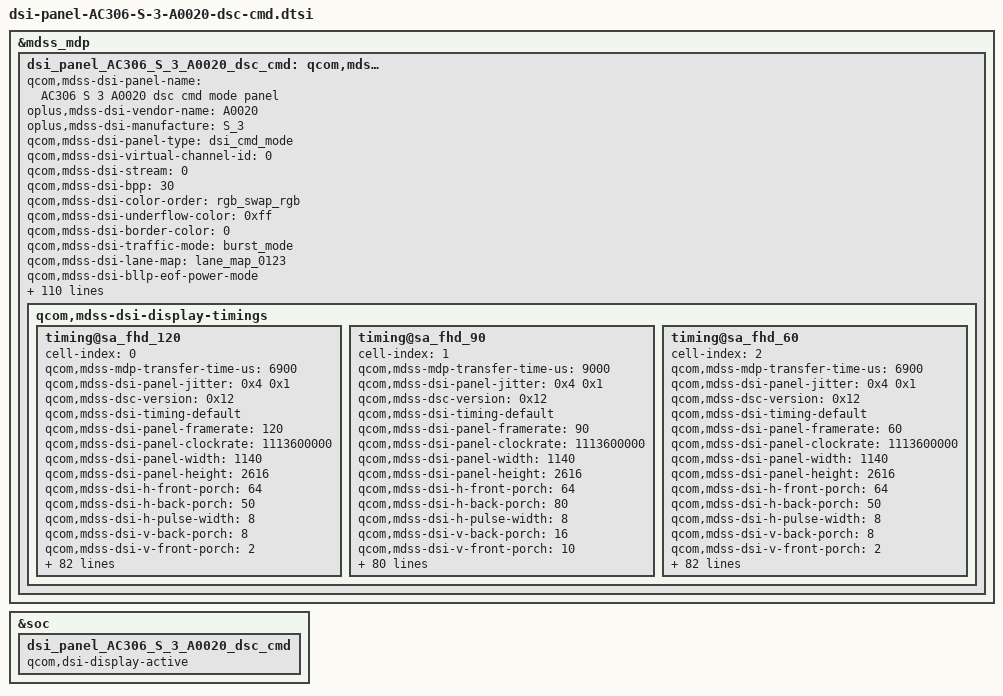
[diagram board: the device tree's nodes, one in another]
&mdss_mdp {
	dsi_panel_AC306_S_3_A0020_dsc_cmd: qcom,mdss_dsi_panel_AC306_S_3_A0020_dsc_cmd {
		qcom,mdss-dsi-panel-name = "AC306 S 3 A0020 dsc cmd mode panel";
		oplus,mdss-dsi-vendor-name = "A0020";
		oplus,mdss-dsi-manufacture = "S_3";
		qcom,mdss-dsi-panel-type = "dsi_cmd_mode";
		qcom,mdss-dsi-virtual-channel-id = <0>;
		qcom,mdss-dsi-stream = <0>;
		qcom,mdss-dsi-bpp = <30>;
		qcom,mdss-dsi-color-order = "rgb_swap_rgb";
		qcom,mdss-dsi-underflow-color = <0xff>;
		qcom,mdss-dsi-border-color = <0>;
		qcom,mdss-dsi-traffic-mode = "burst_mode";
		qcom,mdss-dsi-lane-map = "lane_map_0123";
		qcom,mdss-dsi-bllp-eof-power-mode;
		qcom,mdss-dsi-bllp-power-mode;
		qcom,mdss-dsi-lane-0-state;
		qcom,mdss-dsi-lane-1-state;
		qcom,mdss-dsi-lane-2-state;
		qcom,mdss-dsi-lane-3-state;
		qcom,mdss-dsi-dma-trigger = "trigger_sw";
		qcom,mdss-loading-effect;
		qcom,mdss-dsi-mdp-trigger = "none";
		qcom,mdss-dsi-reset-sequence = <1 2>, <0 5>, <1 30>;
		qcom,mdss-dsi-te-pin-select = <1>;
		qcom,mdss-dsi-te-dcs-command = <1>;
		qcom,mdss-pan-physical-width-dimension = <65>;
		qcom,mdss-pan-physical-height-dimension = <146>;
		qcom,mdss-dsi-init-delay-us = <1000>;
		qcom,mdss-dsi-te-check-enable;
		qcom,mdss-dsi-te-using-te-pin;
		//qcom,mdss-dsi-lp11-init;
		qcom,mdss-dsi-wr-mem-start = <0x2c>;
		qcom,mdss-dsi-wr-mem-continue = <0x3c>;
		qcom,mdss-dsi-panel-jitter = <0x4 0x1>;
		qcom,mdss-dsc-scr-version = <0x1>;
		qcom,mdss-bl-high2bit;
		/* HDR Setting */
		qcom,mdss-dsi-panel-hdr-enabled;
		qcom,mdss-dsi-panel-hdr-color-primaries = <15635 16450 34000 16000 13250 34500 7500 3000>;
		//update for [MPC15]android.mediapc.cts.PerformanceClassTest#testDisplayHdr pass
		//qcom,mdss-dsi-panel-peak-brightness = <16000000>;
		qcom,mdss-dsi-panel-peak-brightness = <22000000>;
		qcom,mdss-dsi-panel-average-brightness = <2000000>;
		qcom,mdss-dsi-panel-blackness-level = <4000>;
		qcom,dynamic-mode-switch-enabled;
		qcom,dynamic-mode-switch-type = "dynamic-resolution-switch-immediate";
		qcom,mdss-dsi-display-timings {
			timing@sa_fhd_120{
				cell-index = <0>;
				#include "dsi-panel-AC306-S-3-A0020-loading-effect.dtsi"
				#include "dsi-panel-AC306-S-3-A0020-common.dtsi"
				qcom,mdss-mdp-transfer-time-us = <6900>;
				qcom,mdss-dsi-panel-jitter = <0x4 0x1>;
				qcom,mdss-dsc-version = <0x12>;
				qcom,mdss-dsi-timing-default;
				qcom,mdss-dsi-panel-framerate = <120>;
				qcom,mdss-dsi-panel-clockrate = <1113600000>;
				qcom,mdss-dsi-panel-width = <1140>;
				qcom,mdss-dsi-panel-height = <2616>;
				qcom,mdss-dsi-h-front-porch = <64>;
				qcom,mdss-dsi-h-back-porch = <50>;
				qcom,mdss-dsi-h-pulse-width = <8>;
				qcom,mdss-dsi-v-back-porch = <8>;
				qcom,mdss-dsi-v-front-porch = <2>;
				qcom,mdss-dsi-v-pulse-width = <2>;
				qcom,mdss-dsi-h-sync-pulse = <0>;

				qcom,mdss-dsi-h-left-border = <0>;
				qcom,mdss-dsi-h-right-border = <0>;
				qcom,mdss-dsi-v-top-border = <0>;
				qcom,mdss-dsi-v-bottom-border = <0>;
				qcom,dsi-mode-te-width-us = <270>;

				/* Apollo vsync config, need to measure TE signal */
				//oplus,apollo-panel-vsync-width = <13000>;
				//oplus,apollo-panel-vsync-period = <16600>;

				oplus,fod-on-vblank = <0>;
				oplus,fod-off-vblank = <0>;

				qcom,mdss-dsi-timing-switch-command = [
					//Switch to 120Hz
					39 00 00 40 00 00 04 FF 5A A5 2D //Page 2D
					39 00 00 40 00 00 03 93 04 00
					39 00 00 40 00 00 03 83 77 00 // Decreasing Step Setting
					15 00 00 40 00 00 02 97 02
					39 00 00 40 00 00 03 98 03 00
					39 00 00 40 00 00 03 99 0B 00
					39 00 00 40 00 00 03 9A 17 00
					39 00 00 40 00 00 03 9B 00 00
					39 00 00 40 00 00 05 A0 00 01 00 00
					39 00 00 40 00 00 05 A1 02 00 00 00
					39 00 00 40 00 00 04 FF 5A A5 00 //Page 0
					15 00 00 40 00 00 02 60 00 //120hz 1 pulse
					39 00 00 40 00 00 04 FF 5A A5 2D //Page 2D
					39 00 00 40 00 00 03 83 00 00 // switch to 120hz
					15 00 00 40 00 00 02 F2 00
					39 00 00 00 00 00 04 FF 5A A5 00 //Page 0
				];
				qcom,mdss-dsi-on-command = [
					39 00 00 40 00 00 04 FF 5A A5 08 // OTP Don’t reload
					15 00 00 40 00 00 02 C8 62
					39 00 00 40 00 00 04 FF 5A A5 07
					15 00 00 40 00 00 02 8A 01
					39 00 00 40 00 00 03 8B 21 E0
					39 00 00 40 00 00 64 81 00 00 00 00 00 12 00 00 AB 21 00 0A 38 04 74 00 0C 02 3A 02 3A 01 55 01 C8 00 0A 00 97 00 2F 00 0C 08 BB 2D 7A 08 00 0C 00 07 10 20 00 06 0F 0F 33 0E 1C 2A 38 46 54 62 69 70 77 79 7B 7D 7E 00 82 11 40 19 C0 22 3E 32 7C 3A BA 3A F8 3B 38 3B 38 3B 76 4B 76 4B 74 4B 74 5B B4 73 F4 01 00 00 00 00 00
					15 00 00 40 00 00 02 91 03
					/* AP SPR */
					39 00 00 40 00 00 04 FF 5A A5 14
					15 00 00 40 00 00 02 80 00
					15 00 00 40 00 00 02 82 01
					39 00 00 00 00 00 04 FF 5A A5 00
					39 00 00 40 00 00 04 FF 5A A5 06 // 1Bist ESD
					15 00 00 40 00 00 02 C6 01
					39 00 00 40 00 00 04 FF 5A A5 08
					15 00 00 40 00 00 02 D2 05
					15 00 00 40 00 00 02 D3 01
					15 00 00 40 00 00 02 E0 22
					39 00 00 40 00 00 04 FF 5A A5 06
					15 00 00 40 00 00 02 A0 00 //scramble disable
					39 00 00 40 00 00 04 FF 5A A5 21 //Page 21
					15 00 00 40 00 00 02 A4 38 //flash reload enable
					39 00 00 40 00 00 04 FF 5A A5 08
					39 00 00 40 00 00 09 ED FF FF FF FF FF FF 45 FF
					39 00 00 40 00 00 09 EE FF FD FF FD F9 FA BE 76
					39 00 00 40 00 00 04 FF 5A A5 00 //Page 0
					15 00 00 40 00 00 02 5E 01 //Skip frame Enable
					15 00 00 40 00 00 02 60 00 //Normal = 120Hz
					15 00 00 40 00 00 02 61 03 //AOD in = 30Hz
					15 00 00 40 00 00 02 35 00 //TE On
					15 00 00 00 00 00 02 53 20 //BC On, Dimming Off
					/* DIC RCN off */
					39 00 00 40 00 00 04 FF 5A A5 17
					15 00 00 40 00 00 02 A0 00
					39 00 00 40 00 00 04 FF 5A A5 13
					15 00 00 00 00 00 02 F9 3C

					39 00 00 40 00 00 04 FF 5A A5 00 //Page 0
					15 00 00 40 00 00 02 60 00 //120hz 1 pulse
					39 00 00 40 00 00 04 FF 5A A5 2D //Page 2D
					39 00 00 40 00 00 03 83 00 00
					39 00 00 40 00 00 03 93 04 00 // Decreasing Step Setting
					15 00 00 40 00 00 02 F2 00
					39 00 00 00 00 00 04 FF 5A A5 00 //Page 0
					/* AOD on/off Black Frame Setting */
					39 00 00 40 00 00 04 FF 5A A5 02
					39 00 00 40 00 00 03 88 C0 00
					39 00 00 00 02 00 04 FF 5A A5 00
					/*sleep out*/
					05 00 00 00 78 00 01 11
					/* ODC */
					39 00 00 40 00 00 04 FF 5A A5 5A
					39 00 00 40 00 00 04 83 2F 14 10
					39 00 00 40 00 00 04 86 42 38 33
					39 00 00 40 00 00 04 8A 18 14 15
					39 00 00 40 00 00 04 8F 14 17 15
					39 00 00 40 00 00 04 90 11 14 13
					39 00 00 40 00 00 04 91 12 16 12
					39 00 00 40 00 00 04 95 18 1D 1D
					39 00 00 40 00 00 04 96 18 18 18
					39 00 00 40 00 00 04 97 12 15 12
					39 00 00 40 00 00 04 98 10 16 12
					39 00 00 40 00 00 04 AA 18 10 13
					39 00 00 40 00 00 04 AC 00 05 04
					39 00 00 40 00 00 04 AD 00 05 04
					39 00 00 40 00 00 04 AE 16 12 10
					39 00 00 40 00 00 04 AF 10 10 10
					39 00 00 40 00 00 04 B0 0D 0D 0D
					39 00 00 40 00 00 04 B1 00 02 00
					39 00 00 40 00 00 04 B2 00 02 00
					39 00 00 40 00 00 04 B3 1D 16 24
					39 00 00 40 00 00 04 B4 14 16 14
					39 00 00 40 00 00 04 B7 06 04 06
					39 00 00 40 00 00 04 B8 05 04 05
					39 00 00 40 00 00 04 B9 30 28 30
					39 00 00 40 00 00 04 BE 07 04 07
					39 00 00 40 00 00 04 BF 06 04 06
					39 00 00 40 00 00 04 C0 39 36 3E
					39 00 00 40 00 00 04 CB 06 08 08
					39 00 00 40 00 00 04 CE 0A 0B 0A
					39 00 00 40 00 00 04 D0 03 05 04
					39 00 00 40 00 00 04 D2 0A 0D 0B
					39 00 00 40 00 00 04 D5 06 02 07
					39 00 00 40 00 00 04 D6 06 02 06
					39 00 00 40 00 00 04 DB 06 03 06
					39 00 00 40 00 00 04 DC 06 03 06
					39 00 00 40 00 00 04 E2 06 02 06
					39 00 00 40 00 00 04 E3 06 02 06
					39 00 00 40 00 00 04 E4 32 36 36
					39 00 00 40 00 00 04 FF 5A A5 5B
					39 00 00 40 00 00 04 A5 04 0A 04
					39 00 00 40 00 00 04 A6 04 06 06
					39 00 00 40 00 00 04 A7 06 08 08
					39 00 00 40 00 00 04 A8 06 0A 08
					39 00 00 40 00 00 04 A9 02 02 02
					39 00 00 40 00 00 04 B1 06 03 06
					39 00 00 40 00 00 04 B2 06 03 06
					39 00 00 40 00 00 04 B9 30 22 30
					39 00 00 40 00 00 04 BE 08 06 06
					39 00 00 40 00 00 04 BF 08 06 06
					39 00 00 40 00 00 04 C0 41 44 45
					39 00 00 40 00 00 04 C9 02 04 04
					39 00 00 40 00 00 04 DB 02 0C 05
					39 00 00 40 00 00 04 DC 02 09 04
					39 00 00 40 00 00 04 E2 02 10 07
					39 00 00 40 00 00 04 E3 02 0D 08
					39 00 00 40 00 00 04 E4 30 36 36
					39 00 00 40 00 00 04 EA 02 11 08
					39 00 00 40 00 00 04 EB 02 0F 05
					39 00 00 40 00 00 04 FF 5A A5 5C
					39 00 00 40 00 00 04 88 04 06 06
					39 00 00 40 00 00 04 89 02 06 05
					39 00 00 40 00 00 04 8A 1A 16 19
					39 00 00 40 00 00 04 8B 1A 16 17
					39 00 00 40 00 00 04 8C 16 12 13
					39 00 00 40 00 00 04 8D 0A 03 08
					39 00 00 40 00 00 04 8E 06 02 03
					39 00 00 40 00 00 04 93 02 06 05
					39 00 00 40 00 00 04 94 02 06 04
					39 00 00 40 00 00 04 95 30 3B 38
					39 00 00 40 00 00 04 9A 02 08 08
					39 00 00 40 00 00 04 9B 02 08 08
					39 00 00 40 00 00 04 9C 4A 40 4A
					39 00 00 40 00 00 04 C8 04 06 04
					39 00 00 00 00 00 04 FF 5A A5 00
					39 00 00 40 00 00 04 FF 5A A5 51
					39 00 00 40 00 00 07 A2 87 7F 80 81 22 22
					39 00 00 00 00 00 04 FF 5A A5 00
                                        /*flexible Gamma*/
                                        39 00 00 40 00 00 04 FF 5A A5 2F
                                        15 00 00 40 00 00 02 99 80
                                        39 00 00 40 00 00 04 FF 5A A5 1F
                                        15 00 00 40 00 00 02 B2 F0
                                        39 00 00 40 00 00 04 FF 5A A5 6E
                                        39 00 00 40 00 00 05 80 67 66 67 66
                                        39 00 00 40 00 00 05 81 67 66 67 66
                                        39 00 00 40 00 00 05 82 67 66 67 66
                                        39 00 00 40 00 00 05 83 67 66 67 66
                                        39 00 00 40 00 00 05 84 67 66 67 66
                                        39 00 00 40 00 00 05 85 67 66 67 66
                                        39 00 00 40 00 00 05 86 67 66 67 66
                                        39 00 00 40 00 00 05 87 67 66 67 66
                                        39 00 00 40 00 00 05 88 67 66 67 66
                                        39 00 00 40 00 00 05 89 67 66 67 66
                                        39 00 00 40 00 00 05 8A 67 66 67 66
                                        39 00 00 40 00 00 05 8B 67 66 67 66
                                        39 00 00 40 00 00 05 8C 67 66 67 66
                                        39 00 00 40 00 00 05 8D 67 66 67 66
                                        39 00 00 40 00 00 05 8E 67 66 67 66
                                        39 00 00 40 00 00 05 8F 67 66 67 66
                                        39 00 00 40 00 00 05 90 67 66 67 66
                                        39 00 00 40 00 00 05 91 67 66 67 66
                                        39 00 00 40 00 00 05 92 67 66 67 66
                                        39 00 00 40 00 00 05 93 67 66 67 66
                                        39 00 00 40 00 00 05 94 67 66 67 66
                                        39 00 00 40 00 00 05 95 67 66 67 66
                                        39 00 00 40 00 00 05 96 67 66 67 66
                                        39 00 00 40 00 00 05 97 67 66 67 66
                                        39 00 00 40 00 00 05 98 67 66 67 66
                                        39 00 00 40 00 00 05 99 67 66 67 66
                                        39 00 00 40 00 00 05 9A 67 66 67 66
                                        39 00 00 40 00 00 05 9B 67 66 67 66
                                        39 00 00 40 00 00 05 9C 67 66 67 66
                                        39 00 00 40 00 00 05 9D 67 66 67 66
                                        39 00 00 40 00 00 05 9E 67 66 67 66
                                        39 00 00 40 00 00 05 9F 67 66 67 66
                                        39 00 00 40 00 00 05 A0 67 66 67 66
                                        39 00 00 40 00 00 05 A1 67 66 67 66
                                        39 00 00 40 00 00 05 A2 67 66 67 66
                                        39 00 00 40 00 00 05 A3 67 66 67 66
                                        39 00 00 40 00 00 05 A4 67 66 67 66
                                        39 00 00 40 00 00 05 A5 67 66 67 66
                                        39 00 00 40 00 00 05 A6 67 66 67 66
                                        39 00 00 40 00 00 05 A7 67 66 67 66
                                        39 00 00 40 00 00 05 A8 66 BE 66 AD
                                        39 00 00 40 00 00 05 A9 66 D8 66 DE
                                        39 00 00 40 00 00 05 AA 67 66 66 D7
                                        39 00 00 40 00 00 05 AB 66 CD 66 C3
                                        39 00 00 40 00 00 05 AC 66 F8 66 FE
                                        39 00 00 40 00 00 05 AD 66 F4 66 ED
                                        39 00 00 40 00 00 05 AE 66 E3 66 19
                                        39 00 00 40 00 00 05 AF 66 14 66 39
                                        39 00 00 40 00 00 05 B0 66 F5 66 C7
                                        39 00 00 40 00 00 05 B1 66 D8 66 AB
                                        39 00 00 40 00 00 05 B2 67 66 67 6E
                                        39 00 00 40 00 00 05 B3 67 70 67 52
                                        39 00 00 40 00 00 05 B4 67 24 67 06
                                        39 00 00 40 00 00 05 B5 67 1B 67 EA
                                        39 00 00 40 00 00 05 B6 67 FC 67 CF
                                        39 00 00 40 00 00 05 B7 67 DE 67 A0
                                        39 00 00 40 00 00 05 B8 66 36 66 C2
                                        39 00 00 40 00 00 05 B9 67 F7 67 E7
                                        39 00 00 40 00 00 05 BA 67 66 67 14
                                        39 00 00 40 00 00 05 BB 67 04 67 35
                                        39 00 00 40 00 00 05 BC 67 22 67 52
                                        39 00 00 40 00 00 05 BD 67 43 67 73
                                        39 00 00 40 00 00 05 BE 66 91 66 81
                                        39 00 00 40 00 00 05 BF 66 AE 66 02
                                        39 00 00 40 00 00 05 C0 66 F3 66 CE
                                        39 00 00 40 00 00 05 C1 66 DC 66 A2
                                        39 00 00 40 00 00 05 C2 67 66 66 B0
                                        39 00 00 40 00 00 05 C3 66 8F 66 94
                                        39 00 00 40 00 00 05 C4 67 63 67 68
                                        39 00 00 40 00 00 05 C5 67 7E 67 47
                                        39 00 00 40 00 00 05 C6 67 4C 67 5B
                                        39 00 00 40 00 00 05 C7 67 20 67 29
                                        39 00 00 40 00 00 05 C8 64 3E 67 F6
                                        39 00 00 40 00 00 05 C9 65 46 67 38
                                        39 00 00 40 00 00 05 CA 67 66 67 92
                                        39 00 00 40 00 00 05 CB 66 8A 66 84
                                        39 00 00 40 00 00 05 CC 66 BF 66 A9
                                        39 00 00 40 00 00 05 CD 66 DD 66 D7
                                        39 00 00 40 00 00 05 CE 66 C1 66 F2
                                        39 00 00 40 00 00 05 CF 66 EC 66 06
                                        39 00 00 40 00 00 05 D0 67 66 67 66
                                        39 00 00 40 00 00 05 D1 67 66 67 66
                                        39 00 00 40 00 00 05 D2 67 66 67 66
                                        39 00 00 40 00 00 05 D3 67 66 67 66
                                        39 00 00 40 00 00 05 D4 67 66 67 66
                                        39 00 00 40 00 00 05 D5 67 66 67 66
                                        39 00 00 40 00 00 05 D6 67 66 67 66
                                        39 00 00 40 00 00 05 D7 67 66 67 66
                                        39 00 00 40 00 00 05 D8 67 66 67 66
                                        39 00 00 40 00 00 05 D9 67 66 67 66
                                        39 00 00 40 00 00 05 DA 67 66 67 66
                                        39 00 00 40 00 00 05 DB 67 66 67 66
                                        39 00 00 40 00 00 05 DC 67 66 67 66
                                        39 00 00 40 00 00 05 DD 67 66 67 66
                                        39 00 00 40 00 00 05 DE 67 66 67 66
                                        39 00 00 40 00 00 05 DF 67 66 67 66
                                        39 00 00 40 00 00 05 E0 67 66 67 66
                                        39 00 00 40 00 00 05 E1 67 66 67 66
                                        39 00 00 40 00 00 05 E2 67 66 67 66
                                        39 00 00 40 00 00 05 E3 67 66 67 66
                                        39 00 00 40 00 00 05 E4 67 66 67 66
                                        39 00 00 40 00 00 05 E5 67 66 67 66
                                        39 00 00 40 00 00 05 E6 67 66 67 66
                                        39 00 00 40 00 00 05 E7 67 66 67 66
                                        39 00 00 40 00 00 04 FF 5A A5 24
                                        15 00 00 40 00 00 02 A1 07
                                        15 00 00 40 00 00 02 A2 C5
                                        15 00 00 40 00 00 02 A3 A4
                                        39 00 00 40 00 00 0D A4 00 00 00 00 00 01 11 22 22 33 33 33
                                        39 00 00 40 00 00 1B D0 0F FE 0D BB 0B 15 07 49 04 7B 04 64 03 E0 02 C6 01 CA 01 3A 00 AA 00 00 00 00
                                        39 00 00 40 00 00 04 FF 5A A5 23
                                        15 00 00 40 00 00 02 D1 01
                                        39 00 00 40 00 00 04 FF 5A A5 1F
                                        15 00 00 40 00 00 02 B2 F0
                                        39 00 00 40 00 00 04 FF 5A A5 6B
                                        39 00 00 40 00 00 05 B3 54 44 24 0E
                                        39 00 00 40 00 00 05 B4 F4 44 24 31
                                        39 00 00 40 00 00 05 B5 57 77 27 B2
                                        39 00 00 40 00 00 05 B6 5E EE 22 9F
                                        39 00 00 40 00 00 05 B7 7F FF 20 BC
                                        39 00 00 40 00 00 05 B8 72 EE 27 04
                                        39 00 00 40 00 00 05 B9 92 22 22 10
                                        39 00 00 40 00 00 05 BA 6F FF 2F 83
                                        39 00 00 40 00 00 05 BB 77 88 28 D8
                                        39 00 00 40 00 00 05 BC 52 22 22 4F
                                        39 00 00 40 00 00 05 BD 66 DD 2D 5B
                                        39 00 00 40 00 00 05 BE 73 33 23 30
                                        39 00 00 40 00 00 05 BF 22 34 25 A6
                                        39 00 00 40 00 00 05 C0 22 54 23 DA
                                        39 00 00 40 00 00 05 C1 22 22 2C BF
                                        39 00 00 40 00 00 05 D7 54 44 23 3B
                                        39 00 00 40 00 00 05 D8 F4 44 23 48
                                        39 00 00 40 00 00 05 D9 57 77 23 CB
                                        39 00 00 40 00 00 05 DA 5E EE 20 98
                                        39 00 00 40 00 00 05 DB 7F FF 21 D9
                                        39 00 00 40 00 00 05 DC 72 EE 24 0E
                                        39 00 00 40 00 00 05 DD 92 22 22 15
                                        39 00 00 40 00 00 05 DE 6F FF 2E 95
                                        39 00 00 40 00 00 05 DF 77 88 28 EA
                                        39 00 00 40 00 00 05 E0 52 22 2E 5F
                                        39 00 00 40 00 00 05 E1 66 DD 2D 38
                                        39 00 00 40 00 00 05 E2 73 33 23 10
                                        39 00 00 40 00 00 05 E3 22 34 24 D6
                                        39 00 00 40 00 00 05 E4 22 54 23 DB
                                        39 00 00 40 00 00 05 E5 22 22 2F CE
                                        39 00 00 40 00 00 04 FF 5A A5 6B
                                        39 00 00 40 00 00 05 8F 22 22 22 22
                                        39 00 00 40 00 00 05 90 22 22 22 22
                                        39 00 00 40 00 00 05 91 22 22 22 22
                                        39 00 00 40 00 00 05 92 22 22 22 22
                                        39 00 00 40 00 00 05 93 22 22 22 22
                                        39 00 00 40 00 00 05 94 22 22 22 22
                                        39 00 00 40 00 00 05 95 22 22 22 22
                                        39 00 00 40 00 00 05 96 22 22 22 22
                                        39 00 00 40 00 00 05 97 22 22 22 22
                                        39 00 00 40 00 00 05 98 22 22 22 22
                                        39 00 00 40 00 00 05 99 22 22 22 22
                                        39 00 00 40 00 00 05 9A 22 22 22 22
                                        39 00 00 40 00 00 05 9B 22 22 22 22
                                        39 00 00 40 00 00 05 9C 22 22 22 22
                                        39 00 00 40 00 00 05 9D 22 22 22 22
                                        39 00 00 40 00 00 04 FF 5A A5 6C
                                        39 00 00 40 00 00 05 83 22 22 22 22
                                        39 00 00 40 00 00 05 84 22 22 22 22
                                        39 00 00 40 00 00 05 85 22 22 22 22
                                        39 00 00 40 00 00 05 86 22 22 22 22
                                        39 00 00 40 00 00 05 87 22 22 22 22
                                        39 00 00 40 00 00 05 88 22 22 22 22
                                        39 00 00 40 00 00 05 89 22 22 22 22
                                        39 00 00 40 00 00 05 8A 22 22 22 22
                                        39 00 00 40 00 00 05 8B 22 22 22 22
                                        39 00 00 40 00 00 05 8C 22 22 22 22
                                        39 00 00 40 00 00 05 8D 22 22 22 22
                                        39 00 00 40 00 00 05 8E 22 22 22 22
                                        39 00 00 40 00 00 05 8F 22 22 22 22
                                        39 00 00 40 00 00 05 90 22 22 22 22
                                        39 00 00 40 00 00 05 91 22 22 22 22
                                        39 00 00 40 00 00 04 FF 5A A5 6C
                                        39 00 00 40 00 00 05 A7 22 22 22 22
                                        39 00 00 40 00 00 05 A8 22 22 22 22
                                        39 00 00 40 00 00 05 A9 22 22 22 22
                                        39 00 00 40 00 00 05 AA 22 22 22 22
                                        39 00 00 40 00 00 05 AB 22 22 22 22
                                        39 00 00 40 00 00 05 AC 22 22 22 22
                                        39 00 00 40 00 00 05 AD 22 22 22 22
                                        39 00 00 40 00 00 05 AE 22 22 22 22
                                        39 00 00 40 00 00 05 AF 22 22 22 22
                                        39 00 00 40 00 00 05 B0 22 22 22 22
                                        39 00 00 40 00 00 05 B1 22 22 22 22
                                        39 00 00 40 00 00 05 B2 22 22 22 22
                                        39 00 00 40 00 00 05 B3 22 22 22 22
                                        39 00 00 40 00 00 05 B4 22 22 22 22
                                        39 00 00 40 00 00 05 B5 22 22 22 22
                                        39 00 00 40 00 00 04 FF 5A A5 6C
                                        39 00 00 40 00 00 05 CB 22 22 22 22
                                        39 00 00 40 00 00 05 CC 22 22 22 22
                                        39 00 00 40 00 00 05 CD 22 22 22 22
                                        39 00 00 40 00 00 05 CE 22 22 22 22
                                        39 00 00 40 00 00 05 CF 22 22 22 22
                                        39 00 00 40 00 00 05 D0 22 22 22 22
                                        39 00 00 40 00 00 05 D1 22 22 22 22
                                        39 00 00 40 00 00 05 D2 22 22 22 22
                                        39 00 00 40 00 00 05 D3 22 22 22 22
                                        39 00 00 40 00 00 05 D4 22 22 22 22
                                        39 00 00 40 00 00 05 D5 22 22 22 22
                                        39 00 00 40 00 00 05 D6 22 22 22 22
                                        39 00 00 40 00 00 05 D7 22 22 22 22
                                        39 00 00 40 00 00 05 D8 22 22 22 22
                                        39 00 00 40 00 00 05 D9 22 22 22 22
                                        39 00 00 40 00 00 04 FF 5A A5 6C
                                        39 00 00 40 00 00 05 EF 22 22 22 22
                                        39 00 00 40 00 00 05 F0 22 22 22 22
                                        39 00 00 40 00 00 05 F1 22 22 22 22
                                        39 00 00 40 00 00 05 F2 22 22 22 22
                                        39 00 00 40 00 00 05 F3 22 22 22 22
                                        39 00 00 40 00 00 05 F4 22 22 22 22
                                        39 00 00 40 00 00 05 F5 22 22 22 22
                                        39 00 00 40 00 00 05 F6 22 22 22 22
                                        39 00 00 40 00 00 05 F7 22 22 22 22
                                        39 00 00 40 00 00 04 FF 5A A5 6D
                                        39 00 00 40 00 00 05 80 22 22 22 22
                                        39 00 00 40 00 00 05 81 22 22 22 22
                                        39 00 00 40 00 00 05 82 22 22 22 22
                                        39 00 00 40 00 00 05 83 22 22 22 22
                                        39 00 00 40 00 00 05 84 22 22 22 22
                                        39 00 00 40 00 00 05 85 22 22 22 22
                                        39 00 00 40 00 00 04 FF 5A A5 6D
                                        39 00 00 40 00 00 05 9B 22 22 22 22
                                        39 00 00 40 00 00 05 9C 22 22 22 22
                                        39 00 00 40 00 00 05 9D 22 22 22 22
                                        39 00 00 40 00 00 05 9E 22 22 22 22
                                        39 00 00 40 00 00 05 9F 22 22 22 22
                                        39 00 00 40 00 00 05 A0 22 22 22 22
                                        39 00 00 40 00 00 05 A1 22 22 22 22
                                        39 00 00 40 00 00 05 A2 22 22 22 22
                                        39 00 00 40 00 00 05 A3 22 22 22 22
                                        39 00 00 40 00 00 05 A4 22 22 22 22
                                        39 00 00 40 00 00 05 A5 22 22 22 22
                                        39 00 00 40 00 00 05 A6 22 22 22 22
                                        39 00 00 40 00 00 05 A7 22 22 22 22
                                        39 00 00 40 00 00 05 A8 22 22 22 22
                                        39 00 00 40 00 00 05 A9 22 22 22 22
                                        39 00 00 40 00 00 04 FF 5A A5 6D
                                        39 00 00 40 00 00 05 B0 22 22 22 22
                                        39 00 00 40 00 00 05 B1 22 22 22 22
                                        39 00 00 40 00 00 05 B2 22 22 22 22
                                        39 00 00 40 00 00 05 B3 22 22 22 22
                                        39 00 00 40 00 00 05 B4 22 22 22 22
                                        39 00 00 40 00 00 05 B5 22 22 22 22
                                        39 00 00 00 00 00 05 B6 22 22 22 22
                                        39 00 00 40 00 00 05 B7 22 22 22 22
                                        39 00 00 40 00 00 05 B8 22 22 22 22
                                        39 00 00 40 00 00 05 B9 22 22 22 22
                                        39 00 00 40 00 00 05 BA 22 22 22 22
                                        39 00 00 40 00 00 05 BB 22 22 22 22
                                        39 00 00 40 00 00 04 FF 5A A5 2F
                                        15 00 00 00 00 00 02 99 00
					/*display on*/
					05 00 00 00 16 00 01 29
				];

				qcom,mdss-dsi-lp1-command = [
					/* AOD mode on */
					39 00 00 40 00 00 04 FF 5A A5 08
					15 00 00 40 00 00 02 98 02 //Queue Start Close CDM FIFO Reset
					39 00 00 40 00 00 04 FF 5A A5 4F // PAGE 4F
					15 00 00 40 00 00 02 81 06
					15 00 00 40 00 00 02 88 78 // cmd core0 queue start
					39 00 00 40 00 00 04 FF 5A A5 05
					15 00 00 40 00 00 02 AE 94
					15 00 00 40 00 00 02 AF DF
					15 00 00 40 00 00 02 B1 9F
					15 00 00 40 00 00 02 B2 DF
					39 00 00 40 00 00 04 C2 3A 20 38
					39 00 00 40 00 00 05 C3 2E 28 2E 2E
					39 00 00 40 00 00 03 C4 2E 22
					39 00 00 40 00 00 04 FF 5A A5 00
					15 00 00 40 00 00 02 6D 00
					39 00 00 40 00 00 04 FF 5A A5 1E
					15 00 00 40 00 00 02 9C 00
					39 00 00 40 00 00 04 FF 5A A5 00
					15 00 00 40 00 00 02 39 00
					39 00 00 40 00 00 04 FF 5A A5 4F
					15 00 00 40 00 00 02 8A 78 // cmd queue set done
					39 00 00 40 00 00 04 FF 5A A5 05
					15 00 00 40 00 00 02 AE 92
					15 00 00 40 00 00 02 AF DA
					15 00 00 40 00 00 02 B1 92
					15 00 00 40 00 00 02 B2 DA
					39 00 00 40 00 00 04 C2 3A 20 3A
					39 00 00 40 00 00 05 C3 2E 2E 2E 2E
					39 00 00 40 00 00 03 C4 2E 2E
					39 00 00 40 00 00 04 FF 5A A5 1E
					15 00 00 40 00 00 02 9C 01
					39 00 00 40 00 00 04 FF 5A A5 00
					15 00 00 40 00 00 02 6D 01
					39 00 00 40 00 00 04 FF 5A A5 08 //ALL Done open CDM FIFO Reset
					15 00 00 40 00 00 02 98 A6
					39 00 00 40 00 00 04 FF 5A A5 00 //Dummy write
					15 00 00 40 00 00 02 00 00
					39 00 00 40 00 00 04 FF 5A A5 4F // PAGE 4F
					15 00 00 40 00 00 02 8B 78 // cmd core 0 queue all done
					39 00 00 40 00 00 04 FF 5A A5 00
					39 00 00 00 00 00 05 51 00 00 03 E0
				];
				qcom,mdss-dsi-nolp-command = [
					/* AOD Mode OFF */
					39 00 00 40 00 00 04 FF 5A A5 00
					15 00 00 00 00 00 02 38 00
				];
				qcom,mdss-dsi-aod-high-mode-command = [
					/* AOD 50nit */
					39 00 00 40 00 00 04 FF 5A A5 00
					39 00 00 00 00 00 05 51 00 00 03 E0
				];
				qcom,mdss-dsi-aod-low-mode-command = [
					/* AOD 10nit */
					39 00 00 40 00 00 04 FF 5A A5 00
					39 00 00 00 00 00 05 51 00 00 01 CA
				];
				qcom,mdss-dsi-ultra-low-power-aod-on-command = [
					39 00 00 40 00 00 04 FF 5A A5 2D
					39 00 00 40 00 00 03 86 1D 00
					39 00 00 00 00 00 04 FF 5A A5 00
                ];
				qcom,mdss-dsi-ultra-low-power-aod-off-command = [
					39 00 00 40 00 00 04 FF 5A A5 2D
					39 00 00 40 00 00 03 86 00 00
					39 00 00 00 00 00 04 FF 5A A5 00
				];
			};
			timing@sa_fhd_90{
				cell-index = <1>;
				#include "dsi-panel-AC306-S-3-A0020-loading-effect.dtsi"
				#include "dsi-panel-AC306-S-3-A0020-common.dtsi"
				qcom,mdss-mdp-transfer-time-us = <9000>;
				qcom,mdss-dsi-panel-jitter = <0x4 0x1>;
				qcom,mdss-dsc-version = <0x12>;
				qcom,mdss-dsi-timing-default;
				qcom,mdss-dsi-panel-framerate = <90>;
				qcom,mdss-dsi-panel-clockrate = <1113600000>;
				qcom,mdss-dsi-panel-width = <1140>;
				qcom,mdss-dsi-panel-height = <2616>;
				qcom,mdss-dsi-h-front-porch = <64>;
				qcom,mdss-dsi-h-back-porch = <80>;
				qcom,mdss-dsi-h-pulse-width = <8>;
				qcom,mdss-dsi-v-back-porch = <16>;
				qcom,mdss-dsi-v-front-porch = <10>;
				qcom,mdss-dsi-v-pulse-width = <2>;
				qcom,mdss-dsi-h-sync-pulse = <0>;

				qcom,mdss-dsi-h-left-border = <0>;
				qcom,mdss-dsi-h-right-border = <0>;
				qcom,mdss-dsi-v-top-border = <0>;
				qcom,mdss-dsi-v-bottom-border = <0>;
				qcom,dsi-mode-te-width-us = <3020>;

				/* Apollo vsync config, need to measure TE signal */
				//oplus,apollo-panel-vsync-width = <13000>;
				//oplus,apollo-panel-vsync-period = <16600>;

				oplus,fod-on-vblank = <0>;
				oplus,fod-off-vblank = <0>;

				qcom,mdss-dsi-timing-switch-command = [
					//Switch to 90Hz
					39 00 00 40 00 00 04 FF 5A A5 2D //Page 2D
					39 00 00 40 00 00 03 93 04 00
					39 00 00 40 00 00 03 84 59 00 // Decreasing Step Setting
					15 00 00 40 00 00 02 A4 02
					39 00 00 40 00 00 03 A5 02 00
					39 00 00 40 00 00 03 A6 08 00
					39 00 00 40 00 00 03 A7 11 00
					39 00 00 40 00 00 03 A8 00 00
					39 00 00 40 00 00 05 AD 00 01 00 00
					39 00 00 40 00 00 05 AE 02 00 00 00
					39 00 00 40 00 00 04 FF 5A A5 00 //Page 0
					15 00 00 40 00 00 02 60 01 //90hz 1 pulse
					39 00 00 40 00 00 04 FF 5A A5 2D //Page 2D
					39 00 00 40 00 00 03 84 00 00 // switch to 90hz
					39 00 00 00 00 00 04 FF 5A A5 00 //Page 0
				];
				qcom,mdss-dsi-on-command = [
					39 00 00 40 00 00 04 FF 5A A5 08 // OTP Don’t reload
					15 00 00 40 00 00 02 C8 62
					39 00 00 40 00 00 04 FF 5A A5 07
					15 00 00 40 00 00 02 8A 01
					39 00 00 40 00 00 03 8B 21 E0
					39 00 00 40 00 00 64 81 00 00 00 00 00 12 00 00 AB 21 00 0A 38 04 74 00 0C 02 3A 02 3A 01 55 01 C8 00 0A 00 97 00 2F 00 0C 08 BB 2D 7A 08 00 0C 00 07 10 20 00 06 0F 0F 33 0E 1C 2A 38 46 54 62 69 70 77 79 7B 7D 7E 00 82 11 40 19 C0 22 3E 32 7C 3A BA 3A F8 3B 38 3B 38 3B 76 4B 76 4B 74 4B 74 5B B4 73 F4 01 00 00 00 00 00
					15 00 00 40 00 00 02 91 03
					/* AP SPR */
					39 00 00 40 00 00 04 FF 5A A5 14
					15 00 00 40 00 00 02 80 00
					15 00 00 40 00 00 02 82 01
					39 00 00 00 00 00 04 FF 5A A5 00
					39 00 00 40 00 00 04 FF 5A A5 06 // 1Bist ESD
					15 00 00 40 00 00 02 C6 01
					39 00 00 40 00 00 04 FF 5A A5 08
					15 00 00 40 00 00 02 D2 05
					15 00 00 40 00 00 02 D3 01
					15 00 00 40 00 00 02 E0 22
					39 00 00 40 00 00 04 FF 5A A5 06
					15 00 00 40 00 00 02 A0 00 //scramble disable
					39 00 00 40 00 00 04 FF 5A A5 21 //Page 21
					15 00 00 40 00 00 02 A4 38 //flash reload enable
					39 00 00 40 00 00 04 FF 5A A5 08
					39 00 00 40 00 00 09 ED FF FF FF FF FF FF 45 FF
					39 00 00 40 00 00 09 EE FF FD FF FD F9 FA BE 76
					39 00 00 40 00 00 04 FF 5A A5 00 //Page 0
					15 00 00 40 00 00 02 5E 01 //Skip frame Enable
					15 00 00 40 00 00 02 60 00 //Normal = 120Hz
					15 00 00 40 00 00 02 61 03 //AOD in = 30Hz
					15 00 00 40 00 00 02 35 00 //TE On
					15 00 00 00 00 00 02 53 20 //BC On, Dimming Off
					/* DIC RCN off */
					39 00 00 40 00 00 04 FF 5A A5 17
					15 00 00 40 00 00 02 A0 00
					39 00 00 40 00 00 04 FF 5A A5 13
					15 00 00 00 00 00 02 F9 3C

					39 00 00 40 00 00 04 FF 5A A5 00 //Page 0
					15 00 00 40 00 00 02 60 01 //90hz 1Pulse
					39 00 00 40 00 00 04 FF 5A A5 2D //Page 2D
					39 00 00 40 00 00 03 84 00 00
					39 00 00 40 00 00 03 93 04 00// Decreasing Step Setting
					39 00 00 00 00 00 04 FF 5A A5 00 //Page 0
					/* AOD on/off Black Frame Setting */
					39 00 00 40 00 00 04 FF 5A A5 02
					39 00 00 40 00 00 03 88 C0 00
					39 00 00 00 02 00 04 FF 5A A5 00
					/*sleep out*/
					05 00 00 00 78 00 01 11
					/* ODC */
					39 00 00 40 00 00 04 FF 5A A5 5A
					39 00 00 40 00 00 04 83 2F 14 10
					39 00 00 40 00 00 04 86 42 38 33
					39 00 00 40 00 00 04 8A 18 14 15
					39 00 00 40 00 00 04 8F 14 17 15
					39 00 00 40 00 00 04 90 11 14 13
					39 00 00 40 00 00 04 91 12 16 12
					39 00 00 40 00 00 04 95 18 1D 1D
					39 00 00 40 00 00 04 96 18 18 18
					39 00 00 40 00 00 04 97 12 15 12
					39 00 00 40 00 00 04 98 10 16 12
					39 00 00 40 00 00 04 AA 18 10 13
					39 00 00 40 00 00 04 AC 00 05 04
					39 00 00 40 00 00 04 AD 00 05 04
					39 00 00 40 00 00 04 AE 16 12 10
					39 00 00 40 00 00 04 AF 10 10 10
					39 00 00 40 00 00 04 B0 0D 0D 0D
					39 00 00 40 00 00 04 B1 00 02 00
					39 00 00 40 00 00 04 B2 00 02 00
					39 00 00 40 00 00 04 B3 1D 16 24
					39 00 00 40 00 00 04 B4 14 16 14
					39 00 00 40 00 00 04 B7 06 04 06
					39 00 00 40 00 00 04 B8 05 04 05
					39 00 00 40 00 00 04 B9 30 28 30
					39 00 00 40 00 00 04 BE 07 04 07
					39 00 00 40 00 00 04 BF 06 04 06
					39 00 00 40 00 00 04 C0 39 36 3E
					39 00 00 40 00 00 04 CB 06 08 08
					39 00 00 40 00 00 04 CE 0A 0B 0A
					39 00 00 40 00 00 04 D0 03 05 04
					39 00 00 40 00 00 04 D2 0A 0D 0B
					39 00 00 40 00 00 04 D5 06 02 07
					39 00 00 40 00 00 04 D6 06 02 06
					39 00 00 40 00 00 04 DB 06 03 06
					39 00 00 40 00 00 04 DC 06 03 06
					39 00 00 40 00 00 04 E2 06 02 06
					39 00 00 40 00 00 04 E3 06 02 06
					39 00 00 40 00 00 04 E4 32 36 36
					39 00 00 40 00 00 04 FF 5A A5 5B
					39 00 00 40 00 00 04 A5 04 0A 04
					39 00 00 40 00 00 04 A6 04 06 06
					39 00 00 40 00 00 04 A7 06 08 08
					39 00 00 40 00 00 04 A8 06 0A 08
					39 00 00 40 00 00 04 A9 02 02 02
					39 00 00 40 00 00 04 B1 06 03 06
					39 00 00 40 00 00 04 B2 06 03 06
					39 00 00 40 00 00 04 B9 30 22 30
					39 00 00 40 00 00 04 BE 08 06 06
					39 00 00 40 00 00 04 BF 08 06 06
					39 00 00 40 00 00 04 C0 41 44 45
					39 00 00 40 00 00 04 C9 02 04 04
					39 00 00 40 00 00 04 DB 02 0C 05
					39 00 00 40 00 00 04 DC 02 09 04
					39 00 00 40 00 00 04 E2 02 10 07
					39 00 00 40 00 00 04 E3 02 0D 08
					39 00 00 40 00 00 04 E4 30 36 36
					39 00 00 40 00 00 04 EA 02 11 08
					39 00 00 40 00 00 04 EB 02 0F 05
					39 00 00 40 00 00 04 FF 5A A5 5C
					39 00 00 40 00 00 04 88 04 06 06
					39 00 00 40 00 00 04 89 02 06 05
					39 00 00 40 00 00 04 8A 1A 16 19
					39 00 00 40 00 00 04 8B 1A 16 17
					39 00 00 40 00 00 04 8C 16 12 13
					39 00 00 40 00 00 04 8D 0A 03 08
					39 00 00 40 00 00 04 8E 06 02 03
					39 00 00 40 00 00 04 93 02 06 05
					39 00 00 40 00 00 04 94 02 06 04
					39 00 00 40 00 00 04 95 30 3B 38
					39 00 00 40 00 00 04 9A 02 08 08
					39 00 00 40 00 00 04 9B 02 08 08
					39 00 00 40 00 00 04 9C 4A 40 4A
					39 00 00 40 00 00 04 C8 04 06 04
					39 00 00 00 00 00 04 FF 5A A5 00
					39 00 00 40 00 00 04 FF 5A A5 51
					39 00 00 40 00 00 07 A2 87 7F 80 81 22 22
					39 00 00 00 00 00 04 FF 5A A5 00
                                        /*flexible Gamma*/
                                        39 00 00 40 00 00 04 FF 5A A5 2F
                                        15 00 00 40 00 00 02 99 80
                                        39 00 00 40 00 00 04 FF 5A A5 1F
                                        15 00 00 40 00 00 02 B2 F0
                                        39 00 00 40 00 00 04 FF 5A A5 6E
                                        39 00 00 40 00 00 05 80 67 66 67 66
                                        39 00 00 40 00 00 05 81 67 66 67 66
                                        39 00 00 40 00 00 05 82 67 66 67 66
                                        39 00 00 40 00 00 05 83 67 66 67 66
                                        39 00 00 40 00 00 05 84 67 66 67 66
                                        39 00 00 40 00 00 05 85 67 66 67 66
                                        39 00 00 40 00 00 05 86 67 66 67 66
                                        39 00 00 40 00 00 05 87 67 66 67 66
                                        39 00 00 40 00 00 05 88 67 66 67 66
                                        39 00 00 40 00 00 05 89 67 66 67 66
                                        39 00 00 40 00 00 05 8A 67 66 67 66
                                        39 00 00 40 00 00 05 8B 67 66 67 66
                                        39 00 00 40 00 00 05 8C 67 66 67 66
                                        39 00 00 40 00 00 05 8D 67 66 67 66
                                        39 00 00 40 00 00 05 8E 67 66 67 66
                                        39 00 00 40 00 00 05 8F 67 66 67 66
                                        39 00 00 40 00 00 05 90 67 66 67 66
                                        39 00 00 40 00 00 05 91 67 66 67 66
                                        39 00 00 40 00 00 05 92 67 66 67 66
                                        39 00 00 40 00 00 05 93 67 66 67 66
                                        39 00 00 40 00 00 05 94 67 66 67 66
                                        39 00 00 40 00 00 05 95 67 66 67 66
                                        39 00 00 40 00 00 05 96 67 66 67 66
                                        39 00 00 40 00 00 05 97 67 66 67 66
                                        39 00 00 40 00 00 05 98 67 66 67 66
                                        39 00 00 40 00 00 05 99 67 66 67 66
                                        39 00 00 40 00 00 05 9A 67 66 67 66
                                        39 00 00 40 00 00 05 9B 67 66 67 66
                                        39 00 00 40 00 00 05 9C 67 66 67 66
                                        39 00 00 40 00 00 05 9D 67 66 67 66
                                        39 00 00 40 00 00 05 9E 67 66 67 66
                                        39 00 00 40 00 00 05 9F 67 66 67 66
                                        39 00 00 40 00 00 05 A0 67 66 67 66
                                        39 00 00 40 00 00 05 A1 67 66 67 66
                                        39 00 00 40 00 00 05 A2 67 66 67 66
                                        39 00 00 40 00 00 05 A3 67 66 67 66
                                        39 00 00 40 00 00 05 A4 67 66 67 66
                                        39 00 00 40 00 00 05 A5 67 66 67 66
                                        39 00 00 40 00 00 05 A6 67 66 67 66
                                        39 00 00 40 00 00 05 A7 67 66 67 66
                                        39 00 00 40 00 00 05 A8 66 BE 66 AD
                                        39 00 00 40 00 00 05 A9 66 D8 66 DE
                                        39 00 00 40 00 00 05 AA 67 66 66 D7
                                        39 00 00 40 00 00 05 AB 66 CD 66 C3
                                        39 00 00 40 00 00 05 AC 66 F8 66 FE
                                        39 00 00 40 00 00 05 AD 66 F4 66 ED
                                        39 00 00 40 00 00 05 AE 66 E3 66 19
                                        39 00 00 40 00 00 05 AF 66 14 66 39
                                        39 00 00 40 00 00 05 B0 66 F5 66 C7
                                        39 00 00 40 00 00 05 B1 66 D8 66 AB
                                        39 00 00 40 00 00 05 B2 67 66 67 6E
                                        39 00 00 40 00 00 05 B3 67 70 67 52
                                        39 00 00 40 00 00 05 B4 67 24 67 06
                                        39 00 00 40 00 00 05 B5 67 1B 67 EA
                                        39 00 00 40 00 00 05 B6 67 FC 67 CF
                                        39 00 00 40 00 00 05 B7 67 DE 67 A0
                                        39 00 00 40 00 00 05 B8 66 36 66 C2
                                        39 00 00 40 00 00 05 B9 67 F7 67 E7
                                        39 00 00 40 00 00 05 BA 67 66 67 14
                                        39 00 00 40 00 00 05 BB 67 04 67 35
                                        39 00 00 40 00 00 05 BC 67 22 67 52
                                        39 00 00 40 00 00 05 BD 67 43 67 73
                                        39 00 00 40 00 00 05 BE 66 91 66 81
                                        39 00 00 40 00 00 05 BF 66 AE 66 02
                                        39 00 00 40 00 00 05 C0 66 F3 66 CE
                                        39 00 00 40 00 00 05 C1 66 DC 66 A2
                                        39 00 00 40 00 00 05 C2 67 66 66 B0
                                        39 00 00 40 00 00 05 C3 66 8F 66 94
                                        39 00 00 40 00 00 05 C4 67 63 67 68
                                        39 00 00 40 00 00 05 C5 67 7E 67 47
                                        39 00 00 40 00 00 05 C6 67 4C 67 5B
                                        39 00 00 40 00 00 05 C7 67 20 67 29
                                        39 00 00 40 00 00 05 C8 64 3E 67 F6
                                        39 00 00 40 00 00 05 C9 65 46 67 38
                                        39 00 00 40 00 00 05 CA 67 66 67 92
                                        39 00 00 40 00 00 05 CB 66 8A 66 84
                                        39 00 00 40 00 00 05 CC 66 BF 66 A9
                                        39 00 00 40 00 00 05 CD 66 DD 66 D7
                                        39 00 00 40 00 00 05 CE 66 C1 66 F2
                                        39 00 00 40 00 00 05 CF 66 EC 66 06
                                        39 00 00 40 00 00 05 D0 67 66 67 66
                                        39 00 00 40 00 00 05 D1 67 66 67 66
                                        39 00 00 40 00 00 05 D2 67 66 67 66
                                        39 00 00 40 00 00 05 D3 67 66 67 66
                                        39 00 00 40 00 00 05 D4 67 66 67 66
                                        39 00 00 40 00 00 05 D5 67 66 67 66
                                        39 00 00 40 00 00 05 D6 67 66 67 66
                                        39 00 00 40 00 00 05 D7 67 66 67 66
                                        39 00 00 40 00 00 05 D8 67 66 67 66
                                        39 00 00 40 00 00 05 D9 67 66 67 66
                                        39 00 00 40 00 00 05 DA 67 66 67 66
                                        39 00 00 40 00 00 05 DB 67 66 67 66
                                        39 00 00 40 00 00 05 DC 67 66 67 66
                                        39 00 00 40 00 00 05 DD 67 66 67 66
                                        39 00 00 40 00 00 05 DE 67 66 67 66
                                        39 00 00 40 00 00 05 DF 67 66 67 66
                                        39 00 00 40 00 00 05 E0 67 66 67 66
                                        39 00 00 40 00 00 05 E1 67 66 67 66
                                        39 00 00 40 00 00 05 E2 67 66 67 66
                                        39 00 00 40 00 00 05 E3 67 66 67 66
                                        39 00 00 40 00 00 05 E4 67 66 67 66
                                        39 00 00 40 00 00 05 E5 67 66 67 66
                                        39 00 00 40 00 00 05 E6 67 66 67 66
                                        39 00 00 40 00 00 05 E7 67 66 67 66
                                        39 00 00 40 00 00 04 FF 5A A5 24
                                        15 00 00 40 00 00 02 A1 07
                                        15 00 00 40 00 00 02 A2 C5
                                        15 00 00 40 00 00 02 A3 A4
                                        39 00 00 40 00 00 0D A4 00 00 00 00 00 01 11 22 22 33 33 33
                                        39 00 00 40 00 00 1B D0 0F FE 0D BB 0B 15 07 49 04 7B 04 64 03 E0 02 C6 01 CA 01 3A 00 AA 00 00 00 00
                                        39 00 00 40 00 00 04 FF 5A A5 23
                                        15 00 00 40 00 00 02 D1 01
                                        39 00 00 40 00 00 04 FF 5A A5 1F
                                        15 00 00 40 00 00 02 B2 F0
                                        39 00 00 40 00 00 04 FF 5A A5 6B
                                        39 00 00 40 00 00 05 B3 54 44 24 0E
                                        39 00 00 40 00 00 05 B4 F4 44 24 31
                                        39 00 00 40 00 00 05 B5 57 77 27 B2
                                        39 00 00 40 00 00 05 B6 5E EE 22 9F
                                        39 00 00 40 00 00 05 B7 7F FF 20 BC
                                        39 00 00 40 00 00 05 B8 72 EE 27 04
                                        39 00 00 40 00 00 05 B9 92 22 22 10
                                        39 00 00 40 00 00 05 BA 6F FF 2F 83
                                        39 00 00 40 00 00 05 BB 77 88 28 D8
                                        39 00 00 40 00 00 05 BC 52 22 22 4F
                                        39 00 00 40 00 00 05 BD 66 DD 2D 5B
                                        39 00 00 40 00 00 05 BE 73 33 23 30
                                        39 00 00 40 00 00 05 BF 22 34 25 A6
                                        39 00 00 40 00 00 05 C0 22 54 23 DA
                                        39 00 00 40 00 00 05 C1 22 22 2C BF
                                        39 00 00 40 00 00 05 D7 54 44 23 3B
                                        39 00 00 40 00 00 05 D8 F4 44 23 48
                                        39 00 00 40 00 00 05 D9 57 77 23 CB
                                        39 00 00 40 00 00 05 DA 5E EE 20 98
                                        39 00 00 40 00 00 05 DB 7F FF 21 D9
                                        39 00 00 40 00 00 05 DC 72 EE 24 0E
                                        39 00 00 40 00 00 05 DD 92 22 22 15
                                        39 00 00 40 00 00 05 DE 6F FF 2E 95
                                        39 00 00 40 00 00 05 DF 77 88 28 EA
                                        39 00 00 40 00 00 05 E0 52 22 2E 5F
                                        39 00 00 40 00 00 05 E1 66 DD 2D 38
                                        39 00 00 40 00 00 05 E2 73 33 23 10
                                        39 00 00 40 00 00 05 E3 22 34 24 D6
                                        39 00 00 40 00 00 05 E4 22 54 23 DB
                                        39 00 00 40 00 00 05 E5 22 22 2F CE
                                        39 00 00 40 00 00 04 FF 5A A5 6B
                                        39 00 00 40 00 00 05 8F 22 22 22 22
                                        39 00 00 40 00 00 05 90 22 22 22 22
                                        39 00 00 40 00 00 05 91 22 22 22 22
                                        39 00 00 40 00 00 05 92 22 22 22 22
                                        39 00 00 40 00 00 05 93 22 22 22 22
                                        39 00 00 40 00 00 05 94 22 22 22 22
                                        39 00 00 40 00 00 05 95 22 22 22 22
                                        39 00 00 40 00 00 05 96 22 22 22 22
                                        39 00 00 40 00 00 05 97 22 22 22 22
                                        39 00 00 40 00 00 05 98 22 22 22 22
                                        39 00 00 40 00 00 05 99 22 22 22 22
                                        39 00 00 40 00 00 05 9A 22 22 22 22
                                        39 00 00 40 00 00 05 9B 22 22 22 22
                                        39 00 00 40 00 00 05 9C 22 22 22 22
                                        39 00 00 40 00 00 05 9D 22 22 22 22
                                        39 00 00 40 00 00 04 FF 5A A5 6C
                                        39 00 00 40 00 00 05 83 22 22 22 22
                                        39 00 00 40 00 00 05 84 22 22 22 22
                                        39 00 00 40 00 00 05 85 22 22 22 22
                                        39 00 00 40 00 00 05 86 22 22 22 22
                                        39 00 00 40 00 00 05 87 22 22 22 22
                                        39 00 00 40 00 00 05 88 22 22 22 22
                                        39 00 00 40 00 00 05 89 22 22 22 22
                                        39 00 00 40 00 00 05 8A 22 22 22 22
                                        39 00 00 40 00 00 05 8B 22 22 22 22
                                        39 00 00 40 00 00 05 8C 22 22 22 22
                                        39 00 00 40 00 00 05 8D 22 22 22 22
                                        39 00 00 40 00 00 05 8E 22 22 22 22
                                        39 00 00 40 00 00 05 8F 22 22 22 22
                                        39 00 00 40 00 00 05 90 22 22 22 22
                                        39 00 00 40 00 00 05 91 22 22 22 22
                                        39 00 00 40 00 00 04 FF 5A A5 6C
                                        39 00 00 40 00 00 05 A7 22 22 22 22
                                        39 00 00 40 00 00 05 A8 22 22 22 22
                                        39 00 00 40 00 00 05 A9 22 22 22 22
                                        39 00 00 40 00 00 05 AA 22 22 22 22
                                        39 00 00 40 00 00 05 AB 22 22 22 22
                                        39 00 00 40 00 00 05 AC 22 22 22 22
                                        39 00 00 40 00 00 05 AD 22 22 22 22
                                        39 00 00 40 00 00 05 AE 22 22 22 22
                                        39 00 00 40 00 00 05 AF 22 22 22 22
                                        39 00 00 40 00 00 05 B0 22 22 22 22
                                        39 00 00 40 00 00 05 B1 22 22 22 22
                                        39 00 00 40 00 00 05 B2 22 22 22 22
                                        39 00 00 40 00 00 05 B3 22 22 22 22
                                        39 00 00 40 00 00 05 B4 22 22 22 22
                                        39 00 00 40 00 00 05 B5 22 22 22 22
                                        39 00 00 40 00 00 04 FF 5A A5 6C
                                        39 00 00 40 00 00 05 CB 22 22 22 22
                                        39 00 00 40 00 00 05 CC 22 22 22 22
                                        39 00 00 40 00 00 05 CD 22 22 22 22
                                        39 00 00 40 00 00 05 CE 22 22 22 22
                                        39 00 00 40 00 00 05 CF 22 22 22 22
                                        39 00 00 40 00 00 05 D0 22 22 22 22
                                        39 00 00 40 00 00 05 D1 22 22 22 22
                                        39 00 00 40 00 00 05 D2 22 22 22 22
                                        39 00 00 40 00 00 05 D3 22 22 22 22
                                        39 00 00 40 00 00 05 D4 22 22 22 22
                                        39 00 00 40 00 00 05 D5 22 22 22 22
                                        39 00 00 40 00 00 05 D6 22 22 22 22
                                        39 00 00 40 00 00 05 D7 22 22 22 22
                                        39 00 00 40 00 00 05 D8 22 22 22 22
                                        39 00 00 40 00 00 05 D9 22 22 22 22
                                        39 00 00 40 00 00 04 FF 5A A5 6C
                                        39 00 00 40 00 00 05 EF 22 22 22 22
                                        39 00 00 40 00 00 05 F0 22 22 22 22
                                        39 00 00 40 00 00 05 F1 22 22 22 22
                                        39 00 00 40 00 00 05 F2 22 22 22 22
                                        39 00 00 40 00 00 05 F3 22 22 22 22
                                        39 00 00 40 00 00 05 F4 22 22 22 22
                                        39 00 00 40 00 00 05 F5 22 22 22 22
                                        39 00 00 40 00 00 05 F6 22 22 22 22
                                        39 00 00 40 00 00 05 F7 22 22 22 22
                                        39 00 00 40 00 00 04 FF 5A A5 6D
                                        39 00 00 40 00 00 05 80 22 22 22 22
                                        39 00 00 40 00 00 05 81 22 22 22 22
                                        39 00 00 40 00 00 05 82 22 22 22 22
                                        39 00 00 40 00 00 05 83 22 22 22 22
                                        39 00 00 40 00 00 05 84 22 22 22 22
                                        39 00 00 40 00 00 05 85 22 22 22 22
                                        39 00 00 40 00 00 04 FF 5A A5 6D
                                        39 00 00 40 00 00 05 9B 22 22 22 22
                                        39 00 00 40 00 00 05 9C 22 22 22 22
                                        39 00 00 40 00 00 05 9D 22 22 22 22
                                        39 00 00 40 00 00 05 9E 22 22 22 22
                                        39 00 00 40 00 00 05 9F 22 22 22 22
                                        39 00 00 40 00 00 05 A0 22 22 22 22
                                        39 00 00 40 00 00 05 A1 22 22 22 22
                                        39 00 00 40 00 00 05 A2 22 22 22 22
                                        39 00 00 40 00 00 05 A3 22 22 22 22
                                        39 00 00 40 00 00 05 A4 22 22 22 22
                                        39 00 00 40 00 00 05 A5 22 22 22 22
                                        39 00 00 40 00 00 05 A6 22 22 22 22
                                        39 00 00 40 00 00 05 A7 22 22 22 22
                                        39 00 00 40 00 00 05 A8 22 22 22 22
                                        39 00 00 40 00 00 05 A9 22 22 22 22
                                        39 00 00 40 00 00 04 FF 5A A5 6D
                                        39 00 00 40 00 00 05 B0 22 22 22 22
                                        39 00 00 40 00 00 05 B1 22 22 22 22
                                        39 00 00 40 00 00 05 B2 22 22 22 22
                                        39 00 00 40 00 00 05 B3 22 22 22 22
                                        39 00 00 40 00 00 05 B4 22 22 22 22
                                        39 00 00 40 00 00 05 B5 22 22 22 22
                                        39 00 00 00 00 00 05 B6 22 22 22 22
                                        39 00 00 40 00 00 05 B7 22 22 22 22
                                        39 00 00 40 00 00 05 B8 22 22 22 22
                                        39 00 00 40 00 00 05 B9 22 22 22 22
                                        39 00 00 40 00 00 05 BA 22 22 22 22
                                        39 00 00 40 00 00 05 BB 22 22 22 22
                                        39 00 00 40 00 00 04 FF 5A A5 2F
                                        15 00 00 00 00 00 02 99 00
					/*display on*/
					05 00 00 00 16 00 01 29
				];

				qcom,mdss-dsi-lp1-command = [
					/* AOD mode on */
					39 00 00 40 00 00 04 FF 5A A5 08
					15 00 00 40 00 00 02 98 02 //Queue Start Close CDM FIFO Reset
					39 00 00 40 00 00 04 FF 5A A5 4F // PAGE 4F
					15 00 00 40 00 00 02 81 06
					15 00 00 40 00 00 02 88 78 // cmd core0 queue start
					39 00 00 40 00 00 04 FF 5A A5 05
					15 00 00 40 00 00 02 AE 94
					15 00 00 40 00 00 02 AF DF
					15 00 00 40 00 00 02 B1 9F
					15 00 00 40 00 00 02 B2 DF
					39 00 00 40 00 00 04 C2 3A 20 38
					39 00 00 40 00 00 05 C3 2E 28 2E 2E
					39 00 00 40 00 00 03 C4 2E 22
					39 00 00 40 00 00 04 FF 5A A5 00
					15 00 00 40 00 00 02 6D 00
					39 00 00 40 00 00 04 FF 5A A5 1E
					15 00 00 40 00 00 02 9C 00
					39 00 00 40 00 00 04 FF 5A A5 00
					15 00 00 40 00 00 02 39 00
					39 00 00 40 00 00 04 FF 5A A5 4F
					15 00 00 40 00 00 02 8A 78 // cmd queue set done
					39 00 00 40 00 00 04 FF 5A A5 05
					15 00 00 40 00 00 02 AE 92
					15 00 00 40 00 00 02 AF DA
					15 00 00 40 00 00 02 B1 92
					15 00 00 40 00 00 02 B2 DA
					39 00 00 40 00 00 04 C2 3A 20 3A
					39 00 00 40 00 00 05 C3 2E 2E 2E 2E
					39 00 00 40 00 00 03 C4 2E 2E
					39 00 00 40 00 00 04 FF 5A A5 1E
					15 00 00 40 00 00 02 9C 01
					39 00 00 40 00 00 04 FF 5A A5 00
					15 00 00 40 00 00 02 6D 01
					39 00 00 40 00 00 04 FF 5A A5 08 //ALL Done open CDM FIFO Reset
					15 00 00 40 00 00 02 98 A6
					39 00 00 40 00 00 04 FF 5A A5 00 //Dummy write
					15 00 00 40 00 00 02 00 00
					39 00 00 40 00 00 04 FF 5A A5 4F // PAGE 4F
					15 00 00 40 00 00 02 8B 78 // cmd core 0 queue all done
					39 00 00 40 00 00 04 FF 5A A5 00
					39 00 00 00 00 00 05 51 00 00 03 D4
				];
				qcom,mdss-dsi-nolp-command = [
					/* AOD Mode OFF */
					39 00 00 40 00 00 04 FF 5A A5 00
					15 00 00 00 00 00 02 38 00
				];
				qcom,mdss-dsi-aod-high-mode-command = [
					/* AOD 50nit */
					39 00 00 40 00 00 04 FF 5A A5 00
					39 00 00 00 00 00 05 51 00 00 03 D4
				];
				qcom,mdss-dsi-aod-low-mode-command = [
					/* AOD 10nit */
					39 00 00 40 00 00 04 FF 5A A5 00
					39 00 00 00 00 00 05 51 00 00 01 B2
				];
				qcom,mdss-dsi-ultra-low-power-aod-on-command = [
					39 00 00 40 00 00 04 FF 5A A5 2D
					39 00 00 40 00 00 03 86 1D 00
					39 00 00 00 00 00 04 FF 5A A5 00
                ];
				qcom,mdss-dsi-ultra-low-power-aod-off-command = [
					39 00 00 40 00 00 04 FF 5A A5 2D
					39 00 00 40 00 00 03 86 00 00
					39 00 00 00 00 00 04 FF 5A A5 00
				];
			};
			timing@sa_fhd_60{
				cell-index = <2>;
				#include "dsi-panel-AC306-S-3-A0020-loading-effect.dtsi"
				#include "dsi-panel-AC306-S-3-A0020-common.dtsi"
				qcom,mdss-mdp-transfer-time-us = <6900>;
				qcom,mdss-dsi-panel-jitter = <0x4 0x1>;
				qcom,mdss-dsc-version = <0x12>;
				qcom,mdss-dsi-timing-default;
				qcom,mdss-dsi-panel-framerate = <60>;
				qcom,mdss-dsi-panel-clockrate = <1113600000>;
				qcom,mdss-dsi-panel-width = <1140>;
				qcom,mdss-dsi-panel-height = <2616>;
				qcom,mdss-dsi-h-front-porch = <64>;
				qcom,mdss-dsi-h-back-porch = <50>;
				qcom,mdss-dsi-h-pulse-width = <8>;
				qcom,mdss-dsi-v-back-porch = <8>;
				qcom,mdss-dsi-v-front-porch = <2>;
				qcom,mdss-dsi-v-pulse-width = <2>;
				qcom,mdss-dsi-h-sync-pulse = <0>;

				qcom,mdss-dsi-h-left-border = <0>;
				qcom,mdss-dsi-h-right-border = <0>;
				qcom,mdss-dsi-v-top-border = <0>;
				qcom,mdss-dsi-v-bottom-border = <0>;
				qcom,dsi-mode-te-width-us = <270>;

				/* Apollo vsync config, need to measure TE signal */
				//oplus,apollo-panel-vsync-width = <13000>;
				//oplus,apollo-panel-vsync-period = <16600>;

				oplus,fod-on-vblank = <0>;
				oplus,fod-off-vblank = <0>;
				oplus,apollo-panel-async-bl-delay = <9000>;
				oplus,apollo-panel-vsync-width = <9000>;

				qcom,mdss-dsi-timing-switch-command = [
					//Switch to 60Hz
					39 00 00 40 00 00 04 FF 5A A5 2D //Page 2D
					39 00 00 40 00 00 03 93 04 00
					39 00 00 40 00 00 03 83 77 00 // Decreasing Step Setting
					15 00 00 40 00 00 02 97 02
					39 00 00 40 00 00 03 98 03 00
					39 00 00 40 00 00 03 99 0B 00
					39 00 00 40 00 00 03 9A 17 00
					39 00 00 40 00 00 03 9B 00 00
					39 00 00 40 00 00 05 A0 00 01 00 00
					39 00 00 40 00 00 05 A1 02 00 00 00
					39 00 00 40 00 00 04 FF 5A A5 00 //Page 0
					15 00 00 40 00 00 02 60 00 //120hz 1Pulse
					39 00 00 40 00 00 04 FF 5A A5 2D //Page 2D
					39 00 00 40 00 00 03 83 01 00 // Decreasing Step Setting
					15 00 00 40 00 00 02 F2 01
					39 00 00 00 00 00 04 FF 5A A5 00 //Page 0
				];
				qcom,mdss-dsi-on-command = [
					39 00 00 40 00 00 04 FF 5A A5 08 // OTP Don’t reload
					15 00 00 40 00 00 02 C8 62
					39 00 00 40 00 00 04 FF 5A A5 07
					15 00 00 40 00 00 02 8A 01
					39 00 00 40 00 00 03 8B 21 E0
					39 00 00 40 00 00 64 81 00 00 00 00 00 12 00 00 AB 21 00 0A 38 04 74 00 0C 02 3A 02 3A 01 55 01 C8 00 0A 00 97 00 2F 00 0C 08 BB 2D 7A 08 00 0C 00 07 10 20 00 06 0F 0F 33 0E 1C 2A 38 46 54 62 69 70 77 79 7B 7D 7E 00 82 11 40 19 C0 22 3E 32 7C 3A BA 3A F8 3B 38 3B 38 3B 76 4B 76 4B 74 4B 74 5B B4 73 F4 01 00 00 00 00 00
					15 00 00 40 00 00 02 91 03
					/* AP SPR */
					39 00 00 40 00 00 04 FF 5A A5 14
					15 00 00 40 00 00 02 80 00
					15 00 00 40 00 00 02 82 01
					39 00 00 00 00 00 04 FF 5A A5 00
					39 00 00 40 00 00 04 FF 5A A5 06 // 1Bist ESD
					15 00 00 40 00 00 02 C6 01
					39 00 00 40 00 00 04 FF 5A A5 08
					15 00 00 40 00 00 02 D2 05
					15 00 00 40 00 00 02 D3 01
					15 00 00 40 00 00 02 E0 22
					39 00 00 40 00 00 04 FF 5A A5 06
					15 00 00 40 00 00 02 A0 00 //scramble disable
					39 00 00 40 00 00 04 FF 5A A5 21 //Page 21
					15 00 00 40 00 00 02 A4 38 //flash reload enable
					39 00 00 40 00 00 04 FF 5A A5 08
					39 00 00 40 00 00 09 ED FF FF FF FF FF FF 45 FF
					39 00 00 40 00 00 09 EE FF FD FF FD F9 FA BE 76
					39 00 00 40 00 00 04 FF 5A A5 00 //Page 0
					15 00 00 40 00 00 02 5E 01 //Skip frame Enable
					15 00 00 40 00 00 02 60 00 //Normal = 120Hz
					15 00 00 40 00 00 02 61 03 //AOD in = 30Hz
					15 00 00 40 00 00 02 35 00 //TE On
					15 00 00 00 00 00 02 53 20 //BC On, Dimming Off
					/* DIC RCN off */
					39 00 00 40 00 00 04 FF 5A A5 17
					15 00 00 40 00 00 02 A0 00
					39 00 00 40 00 00 04 FF 5A A5 13
					15 00 00 00 00 00 02 F9 3C

					39 00 00 40 00 00 04 FF 5A A5 00 //Page 0
					15 00 00 40 00 00 02 60 00 //120hz 1Pulse
					39 00 00 40 00 00 04 FF 5A A5 2D //Page 2D
					39 00 00 40 00 00 03 83 01 00 //120 SKIP 60
					39 00 00 40 00 00 03 93 04 00 // Decreasing Step Setting
					15 00 00 40 00 00 02 F2 01 //120 SKIP 60
					39 00 00 00 00 00 04 FF 5A A5 00 //Page 0
					/* AOD on/off Black Frame Setting */
					39 00 00 40 00 00 04 FF 5A A5 02
					39 00 00 40 00 00 03 88 C0 00
					39 00 00 00 02 00 04 FF 5A A5 00
					/*sleep out*/
					05 00 00 00 78 00 01 11
					/* ODC */
					39 00 00 40 00 00 04 FF 5A A5 5A
					39 00 00 40 00 00 04 83 2F 14 10
					39 00 00 40 00 00 04 86 42 38 33
					39 00 00 40 00 00 04 8A 18 14 15
					39 00 00 40 00 00 04 8F 14 17 15
					39 00 00 40 00 00 04 90 11 14 13
					39 00 00 40 00 00 04 91 12 16 12
					39 00 00 40 00 00 04 95 18 1D 1D
					39 00 00 40 00 00 04 96 18 18 18
					39 00 00 40 00 00 04 97 12 15 12
					39 00 00 40 00 00 04 98 10 16 12
					39 00 00 40 00 00 04 AA 18 10 13
					39 00 00 40 00 00 04 AC 00 05 04
					39 00 00 40 00 00 04 AD 00 05 04
					39 00 00 40 00 00 04 AE 16 12 10
					39 00 00 40 00 00 04 AF 10 10 10
					39 00 00 40 00 00 04 B0 0D 0D 0D
					39 00 00 40 00 00 04 B1 00 02 00
					39 00 00 40 00 00 04 B2 00 02 00
					39 00 00 40 00 00 04 B3 1D 16 24
					39 00 00 40 00 00 04 B4 14 16 14
					39 00 00 40 00 00 04 B7 06 04 06
					39 00 00 40 00 00 04 B8 05 04 05
					39 00 00 40 00 00 04 B9 30 28 30
					39 00 00 40 00 00 04 BE 07 04 07
					39 00 00 40 00 00 04 BF 06 04 06
					39 00 00 40 00 00 04 C0 39 36 3E
					39 00 00 40 00 00 04 CB 06 08 08
					39 00 00 40 00 00 04 CE 0A 0B 0A
					39 00 00 40 00 00 04 D0 03 05 04
					39 00 00 40 00 00 04 D2 0A 0D 0B
					39 00 00 40 00 00 04 D5 06 02 07
					39 00 00 40 00 00 04 D6 06 02 06
					39 00 00 40 00 00 04 DB 06 03 06
					39 00 00 40 00 00 04 DC 06 03 06
					39 00 00 40 00 00 04 E2 06 02 06
					39 00 00 40 00 00 04 E3 06 02 06
					39 00 00 40 00 00 04 E4 32 36 36
					39 00 00 40 00 00 04 FF 5A A5 5B
					39 00 00 40 00 00 04 A5 04 0A 04
					39 00 00 40 00 00 04 A6 04 06 06
					39 00 00 40 00 00 04 A7 06 08 08
					39 00 00 40 00 00 04 A8 06 0A 08
					39 00 00 40 00 00 04 A9 02 02 02
					39 00 00 40 00 00 04 B1 06 03 06
					39 00 00 40 00 00 04 B2 06 03 06
					39 00 00 40 00 00 04 B9 30 22 30
					39 00 00 40 00 00 04 BE 08 06 06
					39 00 00 40 00 00 04 BF 08 06 06
					39 00 00 40 00 00 04 C0 41 44 45
					39 00 00 40 00 00 04 C9 02 04 04
					39 00 00 40 00 00 04 DB 02 0C 05
					39 00 00 40 00 00 04 DC 02 09 04
					39 00 00 40 00 00 04 E2 02 10 07
					39 00 00 40 00 00 04 E3 02 0D 08
					39 00 00 40 00 00 04 E4 30 36 36
					39 00 00 40 00 00 04 EA 02 11 08
					39 00 00 40 00 00 04 EB 02 0F 05
					39 00 00 40 00 00 04 FF 5A A5 5C
					39 00 00 40 00 00 04 88 04 06 06
					39 00 00 40 00 00 04 89 02 06 05
					39 00 00 40 00 00 04 8A 1A 16 19
					39 00 00 40 00 00 04 8B 1A 16 17
					39 00 00 40 00 00 04 8C 16 12 13
					39 00 00 40 00 00 04 8D 0A 03 08
					39 00 00 40 00 00 04 8E 06 02 03
					39 00 00 40 00 00 04 93 02 06 05
					39 00 00 40 00 00 04 94 02 06 04
					39 00 00 40 00 00 04 95 30 3B 38
					39 00 00 40 00 00 04 9A 02 08 08
					39 00 00 40 00 00 04 9B 02 08 08
					39 00 00 40 00 00 04 9C 4A 40 4A
					39 00 00 40 00 00 04 C8 04 06 04
					39 00 00 00 00 00 04 FF 5A A5 00
					39 00 00 40 00 00 04 FF 5A A5 51
					39 00 00 40 00 00 07 A2 87 7F 80 81 22 22
					39 00 00 00 00 00 04 FF 5A A5 00
                                       /*flexible Gamma*/
                                       39 00 00 40 00 00 04 FF 5A A5 2F
                                       15 00 00 40 00 00 02 99 80
                                       39 00 00 40 00 00 04 FF 5A A5 1F
                                       15 00 00 40 00 00 02 B2 F0
                                       39 00 00 40 00 00 04 FF 5A A5 6E
                                       39 00 00 40 00 00 05 80 67 66 67 66
                                       39 00 00 40 00 00 05 81 67 66 67 66
                                       39 00 00 40 00 00 05 82 67 66 67 66
                                       39 00 00 40 00 00 05 83 67 66 67 66
                                       39 00 00 40 00 00 05 84 67 66 67 66
                                       39 00 00 40 00 00 05 85 67 66 67 66
                                       39 00 00 40 00 00 05 86 67 66 67 66
                                       39 00 00 40 00 00 05 87 67 66 67 66
                                       39 00 00 40 00 00 05 88 67 66 67 66
                                       39 00 00 40 00 00 05 89 67 66 67 66
                                       39 00 00 40 00 00 05 8A 67 66 67 66
                                       39 00 00 40 00 00 05 8B 67 66 67 66
                                       39 00 00 40 00 00 05 8C 67 66 67 66
                                       39 00 00 40 00 00 05 8D 67 66 67 66
                                       39 00 00 40 00 00 05 8E 67 66 67 66
                                       39 00 00 40 00 00 05 8F 67 66 67 66
                                       39 00 00 40 00 00 05 90 67 66 67 66
                                       39 00 00 40 00 00 05 91 67 66 67 66
                                       39 00 00 40 00 00 05 92 67 66 67 66
                                       39 00 00 40 00 00 05 93 67 66 67 66
                                       39 00 00 40 00 00 05 94 67 66 67 66
                                       39 00 00 40 00 00 05 95 67 66 67 66
                                       39 00 00 40 00 00 05 96 67 66 67 66
                                       39 00 00 40 00 00 05 97 67 66 67 66
                                       39 00 00 40 00 00 05 98 67 66 67 66
                                       39 00 00 40 00 00 05 99 67 66 67 66
                                       39 00 00 40 00 00 05 9A 67 66 67 66
                                       39 00 00 40 00 00 05 9B 67 66 67 66
                                       39 00 00 40 00 00 05 9C 67 66 67 66
                                       39 00 00 40 00 00 05 9D 67 66 67 66
                                       39 00 00 40 00 00 05 9E 67 66 67 66
                                       39 00 00 40 00 00 05 9F 67 66 67 66
                                       39 00 00 40 00 00 05 A0 67 66 67 66
                                       39 00 00 40 00 00 05 A1 67 66 67 66
                                       39 00 00 40 00 00 05 A2 67 66 67 66
                                       39 00 00 40 00 00 05 A3 67 66 67 66
                                       39 00 00 40 00 00 05 A4 67 66 67 66
                                       39 00 00 40 00 00 05 A5 67 66 67 66
                                       39 00 00 40 00 00 05 A6 67 66 67 66
                                       39 00 00 40 00 00 05 A7 67 66 67 66
                                       39 00 00 40 00 00 05 A8 66 BE 66 AD
                                       39 00 00 40 00 00 05 A9 66 D8 66 DE
                                       39 00 00 40 00 00 05 AA 67 66 66 D7
                                       39 00 00 40 00 00 05 AB 66 CD 66 C3
                                       39 00 00 40 00 00 05 AC 66 F8 66 FE
                                       39 00 00 40 00 00 05 AD 66 F4 66 ED
                                       39 00 00 40 00 00 05 AE 66 E3 66 19
                                       39 00 00 40 00 00 05 AF 66 14 66 39
                                       39 00 00 40 00 00 05 B0 66 F5 66 C7
                                       39 00 00 40 00 00 05 B1 66 D8 66 AB
                                       39 00 00 40 00 00 05 B2 67 66 67 6E
                                       39 00 00 40 00 00 05 B3 67 70 67 52
                                       39 00 00 40 00 00 05 B4 67 24 67 06
                                       39 00 00 40 00 00 05 B5 67 1B 67 EA
                                       39 00 00 40 00 00 05 B6 67 FC 67 CF
                                       39 00 00 40 00 00 05 B7 67 DE 67 A0
                                       39 00 00 40 00 00 05 B8 66 36 66 C2
                                       39 00 00 40 00 00 05 B9 67 F7 67 E7
                                       39 00 00 40 00 00 05 BA 67 66 67 14
                                       39 00 00 40 00 00 05 BB 67 04 67 35
                                       39 00 00 40 00 00 05 BC 67 22 67 52
                                       39 00 00 40 00 00 05 BD 67 43 67 73
                                       39 00 00 40 00 00 05 BE 66 91 66 81
                                       39 00 00 40 00 00 05 BF 66 AE 66 02
                                       39 00 00 40 00 00 05 C0 66 F3 66 CE
                                       39 00 00 40 00 00 05 C1 66 DC 66 A2
                                       39 00 00 40 00 00 05 C2 67 66 66 B0
                                       39 00 00 40 00 00 05 C3 66 8F 66 94
                                       39 00 00 40 00 00 05 C4 67 63 67 68
                                       39 00 00 40 00 00 05 C5 67 7E 67 47
                                       39 00 00 40 00 00 05 C6 67 4C 67 5B
                                       39 00 00 40 00 00 05 C7 67 20 67 29
                                       39 00 00 40 00 00 05 C8 64 3E 67 F6
                                       39 00 00 40 00 00 05 C9 65 46 67 38
                                       39 00 00 40 00 00 05 CA 67 66 67 92
                                       39 00 00 40 00 00 05 CB 66 8A 66 84
                                       39 00 00 40 00 00 05 CC 66 BF 66 A9
                                       39 00 00 40 00 00 05 CD 66 DD 66 D7
                                       39 00 00 40 00 00 05 CE 66 C1 66 F2
                                       39 00 00 40 00 00 05 CF 66 EC 66 06
                                       39 00 00 40 00 00 05 D0 67 66 67 66
                                       39 00 00 40 00 00 05 D1 67 66 67 66
                                       39 00 00 40 00 00 05 D2 67 66 67 66
                                       39 00 00 40 00 00 05 D3 67 66 67 66
                                       39 00 00 40 00 00 05 D4 67 66 67 66
                                       39 00 00 40 00 00 05 D5 67 66 67 66
                                       39 00 00 40 00 00 05 D6 67 66 67 66
                                       39 00 00 40 00 00 05 D7 67 66 67 66
                                       39 00 00 40 00 00 05 D8 67 66 67 66
                                       39 00 00 40 00 00 05 D9 67 66 67 66
                                       39 00 00 40 00 00 05 DA 67 66 67 66
                                       39 00 00 40 00 00 05 DB 67 66 67 66
                                       39 00 00 40 00 00 05 DC 67 66 67 66
                                       39 00 00 40 00 00 05 DD 67 66 67 66
                                       39 00 00 40 00 00 05 DE 67 66 67 66
                                       39 00 00 40 00 00 05 DF 67 66 67 66
                                       39 00 00 40 00 00 05 E0 67 66 67 66
                                       39 00 00 40 00 00 05 E1 67 66 67 66
                                       39 00 00 40 00 00 05 E2 67 66 67 66
                                       39 00 00 40 00 00 05 E3 67 66 67 66
                                       39 00 00 40 00 00 05 E4 67 66 67 66
                                       39 00 00 40 00 00 05 E5 67 66 67 66
                                       39 00 00 40 00 00 05 E6 67 66 67 66
                                       39 00 00 40 00 00 05 E7 67 66 67 66
                                       39 00 00 40 00 00 04 FF 5A A5 24
                                       15 00 00 40 00 00 02 A1 07
                                       15 00 00 40 00 00 02 A2 C5
                                       15 00 00 40 00 00 02 A3 A4
                                       39 00 00 40 00 00 0D A4 00 00 00 00 00 01 11 22 22 33 33 33
                                       39 00 00 40 00 00 1B D0 0F FE 0D BB 0B 15 07 49 04 7B 04 64 03 E0 02 C6 01 CA 01 3A 00 AA 00 00 00 00
                                       39 00 00 40 00 00 04 FF 5A A5 23
                                       15 00 00 40 00 00 02 D1 01
                                       39 00 00 40 00 00 04 FF 5A A5 1F
                                       15 00 00 40 00 00 02 B2 F0
                                       39 00 00 40 00 00 04 FF 5A A5 6B
                                       39 00 00 40 00 00 05 B3 54 44 24 0E
                                       39 00 00 40 00 00 05 B4 F4 44 24 31
                                       39 00 00 40 00 00 05 B5 57 77 27 B2
                                       39 00 00 40 00 00 05 B6 5E EE 22 9F
                                       39 00 00 40 00 00 05 B7 7F FF 20 BC
                                       39 00 00 40 00 00 05 B8 72 EE 27 04
                                       39 00 00 40 00 00 05 B9 92 22 22 10
                                       39 00 00 40 00 00 05 BA 6F FF 2F 83
                                       39 00 00 40 00 00 05 BB 77 88 28 D8
                                       39 00 00 40 00 00 05 BC 52 22 22 4F
                                       39 00 00 40 00 00 05 BD 66 DD 2D 5B
                                       39 00 00 40 00 00 05 BE 73 33 23 30
                                       39 00 00 40 00 00 05 BF 22 34 25 A6
                                       39 00 00 40 00 00 05 C0 22 54 23 DA
                                       39 00 00 40 00 00 05 C1 22 22 2C BF
                                       39 00 00 40 00 00 05 D7 54 44 23 3B
                                       39 00 00 40 00 00 05 D8 F4 44 23 48
                                       39 00 00 40 00 00 05 D9 57 77 23 CB
                                       39 00 00 40 00 00 05 DA 5E EE 20 98
                                       39 00 00 40 00 00 05 DB 7F FF 21 D9
                                       39 00 00 40 00 00 05 DC 72 EE 24 0E
                                       39 00 00 40 00 00 05 DD 92 22 22 15
                                       39 00 00 40 00 00 05 DE 6F FF 2E 95
                                       39 00 00 40 00 00 05 DF 77 88 28 EA
                                       39 00 00 40 00 00 05 E0 52 22 2E 5F
                                       39 00 00 40 00 00 05 E1 66 DD 2D 38
                                       39 00 00 40 00 00 05 E2 73 33 23 10
                                       39 00 00 40 00 00 05 E3 22 34 24 D6
                                       39 00 00 40 00 00 05 E4 22 54 23 DB
                                       39 00 00 40 00 00 05 E5 22 22 2F CE
                                       39 00 00 40 00 00 04 FF 5A A5 6B
                                       39 00 00 40 00 00 05 8F 22 22 22 22
                                       39 00 00 40 00 00 05 90 22 22 22 22
                                       39 00 00 40 00 00 05 91 22 22 22 22
                                       39 00 00 40 00 00 05 92 22 22 22 22
                                       39 00 00 40 00 00 05 93 22 22 22 22
                                       39 00 00 40 00 00 05 94 22 22 22 22
                                       39 00 00 40 00 00 05 95 22 22 22 22
                                       39 00 00 40 00 00 05 96 22 22 22 22
                                       39 00 00 40 00 00 05 97 22 22 22 22
                                       39 00 00 40 00 00 05 98 22 22 22 22
                                       39 00 00 40 00 00 05 99 22 22 22 22
                                       39 00 00 40 00 00 05 9A 22 22 22 22
                                       39 00 00 40 00 00 05 9B 22 22 22 22
                                       39 00 00 40 00 00 05 9C 22 22 22 22
                                       39 00 00 40 00 00 05 9D 22 22 22 22
                                       39 00 00 40 00 00 04 FF 5A A5 6C
                                       39 00 00 40 00 00 05 83 22 22 22 22
                                       39 00 00 40 00 00 05 84 22 22 22 22
                                       39 00 00 40 00 00 05 85 22 22 22 22
                                       39 00 00 40 00 00 05 86 22 22 22 22
                                       39 00 00 40 00 00 05 87 22 22 22 22
                                       39 00 00 40 00 00 05 88 22 22 22 22
                                       39 00 00 40 00 00 05 89 22 22 22 22
                                       39 00 00 40 00 00 05 8A 22 22 22 22
                                       39 00 00 40 00 00 05 8B 22 22 22 22
                                       39 00 00 40 00 00 05 8C 22 22 22 22
                                       39 00 00 40 00 00 05 8D 22 22 22 22
                                       39 00 00 40 00 00 05 8E 22 22 22 22
                                       39 00 00 40 00 00 05 8F 22 22 22 22
                                       39 00 00 40 00 00 05 90 22 22 22 22
                                       39 00 00 40 00 00 05 91 22 22 22 22
                                       39 00 00 40 00 00 04 FF 5A A5 6C
                                       39 00 00 40 00 00 05 A7 22 22 22 22
                                       39 00 00 40 00 00 05 A8 22 22 22 22
                                       39 00 00 40 00 00 05 A9 22 22 22 22
                                       39 00 00 40 00 00 05 AA 22 22 22 22
                                       39 00 00 40 00 00 05 AB 22 22 22 22
                                       39 00 00 40 00 00 05 AC 22 22 22 22
                                       39 00 00 40 00 00 05 AD 22 22 22 22
                                       39 00 00 40 00 00 05 AE 22 22 22 22
                                       39 00 00 40 00 00 05 AF 22 22 22 22
                                       39 00 00 40 00 00 05 B0 22 22 22 22
                                       39 00 00 40 00 00 05 B1 22 22 22 22
                                       39 00 00 40 00 00 05 B2 22 22 22 22
                                       39 00 00 40 00 00 05 B3 22 22 22 22
                                       39 00 00 40 00 00 05 B4 22 22 22 22
                                       39 00 00 40 00 00 05 B5 22 22 22 22
                                       39 00 00 40 00 00 04 FF 5A A5 6C
                                       39 00 00 40 00 00 05 CB 22 22 22 22
                                       39 00 00 40 00 00 05 CC 22 22 22 22
                                       39 00 00 40 00 00 05 CD 22 22 22 22
                                       39 00 00 40 00 00 05 CE 22 22 22 22
                                       39 00 00 40 00 00 05 CF 22 22 22 22
                                       39 00 00 40 00 00 05 D0 22 22 22 22
                                       39 00 00 40 00 00 05 D1 22 22 22 22
                                       39 00 00 40 00 00 05 D2 22 22 22 22
                                       39 00 00 40 00 00 05 D3 22 22 22 22
                                       39 00 00 40 00 00 05 D4 22 22 22 22
                                       39 00 00 40 00 00 05 D5 22 22 22 22
                                       39 00 00 40 00 00 05 D6 22 22 22 22
                                       39 00 00 40 00 00 05 D7 22 22 22 22
                                       39 00 00 40 00 00 05 D8 22 22 22 22
                                       39 00 00 40 00 00 05 D9 22 22 22 22
                                       39 00 00 40 00 00 04 FF 5A A5 6C
                                       39 00 00 40 00 00 05 EF 22 22 22 22
                                       39 00 00 40 00 00 05 F0 22 22 22 22
                                       39 00 00 40 00 00 05 F1 22 22 22 22
                                       39 00 00 40 00 00 05 F2 22 22 22 22
                                       39 00 00 40 00 00 05 F3 22 22 22 22
                                       39 00 00 40 00 00 05 F4 22 22 22 22
                                       39 00 00 40 00 00 05 F5 22 22 22 22
                                       39 00 00 40 00 00 05 F6 22 22 22 22
                                       39 00 00 40 00 00 05 F7 22 22 22 22
                                       39 00 00 40 00 00 04 FF 5A A5 6D
                                       39 00 00 40 00 00 05 80 22 22 22 22
                                       39 00 00 40 00 00 05 81 22 22 22 22
                                       39 00 00 40 00 00 05 82 22 22 22 22
                                       39 00 00 40 00 00 05 83 22 22 22 22
                                       39 00 00 40 00 00 05 84 22 22 22 22
                                       39 00 00 40 00 00 05 85 22 22 22 22
                                       39 00 00 40 00 00 04 FF 5A A5 6D
                                       39 00 00 40 00 00 05 9B 22 22 22 22
                                       39 00 00 40 00 00 05 9C 22 22 22 22
                                       39 00 00 40 00 00 05 9D 22 22 22 22
                                       39 00 00 40 00 00 05 9E 22 22 22 22
                                       39 00 00 40 00 00 05 9F 22 22 22 22
                                       39 00 00 40 00 00 05 A0 22 22 22 22
                                       39 00 00 40 00 00 05 A1 22 22 22 22
                                       39 00 00 40 00 00 05 A2 22 22 22 22
                                       39 00 00 40 00 00 05 A3 22 22 22 22
                                       39 00 00 40 00 00 05 A4 22 22 22 22
                                       39 00 00 40 00 00 05 A5 22 22 22 22
                                       39 00 00 40 00 00 05 A6 22 22 22 22
                                       39 00 00 40 00 00 05 A7 22 22 22 22
                                       39 00 00 40 00 00 05 A8 22 22 22 22
                                       39 00 00 40 00 00 05 A9 22 22 22 22
                                       39 00 00 40 00 00 04 FF 5A A5 6D
                                       39 00 00 40 00 00 05 B0 22 22 22 22
                                       39 00 00 40 00 00 05 B1 22 22 22 22
                                       39 00 00 40 00 00 05 B2 22 22 22 22
                                       39 00 00 40 00 00 05 B3 22 22 22 22
                                       39 00 00 40 00 00 05 B4 22 22 22 22
                                       39 00 00 40 00 00 05 B5 22 22 22 22
                                       39 00 00 00 00 00 05 B6 22 22 22 22
                                       39 00 00 40 00 00 05 B7 22 22 22 22
                                       39 00 00 40 00 00 05 B8 22 22 22 22
                                       39 00 00 40 00 00 05 B9 22 22 22 22
                                       39 00 00 40 00 00 05 BA 22 22 22 22
                                       39 00 00 40 00 00 05 BB 22 22 22 22
                                       39 00 00 40 00 00 04 FF 5A A5 2F
                                       15 00 00 00 00 00 02 99 00
					/*display on*/
					05 00 00 00 16 00 01 29
				];

				qcom,mdss-dsi-lp1-command = [
					/* AOD mode on */
					39 00 00 40 00 00 04 FF 5A A5 08
					15 00 00 40 00 00 02 98 02 //Queue Start Close CDM FIFO Reset
					39 00 00 40 00 00 04 FF 5A A5 4F // PAGE 4F
					15 00 00 40 00 00 02 81 06
					15 00 00 40 00 00 02 88 78 // cmd core0 queue start
					39 00 00 40 00 00 04 FF 5A A5 05
					15 00 00 40 00 00 02 AE 94
					15 00 00 40 00 00 02 AF DF
					15 00 00 40 00 00 02 B1 9F
					15 00 00 40 00 00 02 B2 DF
					39 00 00 40 00 00 04 C2 3A 20 38
					39 00 00 40 00 00 05 C3 2E 28 2E 2E
					39 00 00 40 00 00 03 C4 2E 22
					39 00 00 40 00 00 04 FF 5A A5 00
					15 00 00 40 00 00 02 6D 00
					39 00 00 40 00 00 04 FF 5A A5 1E
					15 00 00 40 00 00 02 9C 00
					39 00 00 40 00 00 04 FF 5A A5 00
					15 00 00 40 00 00 02 39 00
					39 00 00 40 00 00 04 FF 5A A5 4F
					15 00 00 40 00 00 02 8A 78 // cmd queue set done
					39 00 00 40 00 00 04 FF 5A A5 05
					15 00 00 40 00 00 02 AE 92
					15 00 00 40 00 00 02 AF DA
					15 00 00 40 00 00 02 B1 92
					15 00 00 40 00 00 02 B2 DA
					39 00 00 40 00 00 04 C2 3A 20 3A
					39 00 00 40 00 00 05 C3 2E 2E 2E 2E
					39 00 00 40 00 00 03 C4 2E 2E
					39 00 00 40 00 00 04 FF 5A A5 1E
					15 00 00 40 00 00 02 9C 01
					39 00 00 40 00 00 04 FF 5A A5 00
					15 00 00 40 00 00 02 6D 01
					39 00 00 40 00 00 04 FF 5A A5 08 //ALL Done open CDM FIFO Reset
					15 00 00 40 00 00 02 98 A6
					39 00 00 40 00 00 04 FF 5A A5 00 //Dummy write
					15 00 00 40 00 00 02 00 00
					39 00 00 40 00 00 04 FF 5A A5 4F // PAGE 4F
					15 00 00 40 00 00 02 8B 78 // cmd core 0 queue all done
					39 00 00 40 00 00 04 FF 5A A5 00
					39 00 00 00 00 00 05 51 00 00 03 D4
				];
				qcom,mdss-dsi-nolp-command = [
					/* AOD Mode OFF */
					39 00 00 40 00 00 04 FF 5A A5 00
					15 00 00 00 00 00 02 38 00
				];
				qcom,mdss-dsi-aod-high-mode-command = [
					/* AOD 50nit */
					39 00 00 40 00 00 04 FF 5A A5 00
					39 00 00 00 00 00 05 51 00 00 03 D4
				];
				qcom,mdss-dsi-aod-low-mode-command = [
					/* AOD 10nit */
					39 00 00 40 00 00 04 FF 5A A5 00
					39 00 00 00 00 00 05 51 00 00 01 B2
				];
				qcom,mdss-dsi-ultra-low-power-aod-on-command = [
					39 00 00 40 00 00 04 FF 5A A5 2D
					39 00 00 40 00 00 03 86 1D 00
					39 00 00 00 00 00 04 FF 5A A5 00
                ];
				qcom,mdss-dsi-ultra-low-power-aod-off-command = [
					39 00 00 40 00 00 04 FF 5A A5 2D
					39 00 00 40 00 00 03 86 00 00
					39 00 00 00 00 00 04 FF 5A A5 00
				];
			};
		};
	};
};

&soc {
	dsi_panel_AC306_S_3_A0020_dsc_cmd {
		qcom,dsi-display-active;
	};
};

&dsi_panel_AC306_S_3_A0020_dsc_cmd {
	qcom,panel-sec-supply-entries = <&dsi_panel_pwr_supply_sim>;
	qcom,mdss-dsi-sec-bl-pmic-control-type = "bl_ctrl_dcs";
	qcom,bl-update-flag = "delay_until_first_frame";
	qcom,mdss-dsi-bl-min-level = <1>;
	qcom,mdss-dsi-bl-max-level = <4094>;
	qcom,mdss-brightness-max-level = <4094>;
	oplus,dsi-bl-normal-max-level = <3515>;
	oplus,dsi-brightness-normal-max-level = <3515>;
	oplus,dsi-dc-backlight-threshold = <1960>;
	oplus,dsi-brightness-default-level = <1638>;
	oplus,dsi_demura2_offset_support;

	qcom,mdss-dsi-bl-inverted-dbv;
	qcom,ulps-enabled;

	qcom,platform-sec-reset-gpio = <&awgpio 12 0>;
	oplus,panel-gpio1 = <&awgpio 10 0>;
	oplus,panel-gpio2 = <&awgpio 11 0>;
	oplus,panel-gpio3 = <&awgpio 9 0>;

	oplus,panel-reset-position = <0x02>;
	oplus,panel-power-on-sequence = "1", "gpio1", "3", "gpio2", "3", "gpio3", "10";
	oplus,panel-power-off-sequence = "1", "gpio3", "3", "gpio2", "3", "gpio1", "1";

	/* a pair of oplus pinctrl names, in order [active, suspend] */
	//oplus,dsi-pinctrl-names = "oplus_panel_active", "oplus_panel_suspend";
	//qcom,dsi-ctrl-num = <1>;
	//qcom,dsi-phy-num = <1>;
	//qcom,dsi-select-clocks = "pll_byte_clk1", "pll_dsi_clk1";

	qcom,dsi-sec-ctrl-num = <1>;
	qcom,dsi-sec-phy-num = <1>;
	qcom,dsi-select-sec-clocks = "pll_byte_clk1", "pll_dsi_clk1";

	/* ofp config */
	oplus,ofp-fp-type = <0x82>;
	oplus,ofp-longrui-aod-config = <0x0E>;
	oplus,ofp-need-to-wait-data-before-aod-on;

	qcom,mdss-dsi-display-timings {
		timing@sa_fhd_120 { /* FHD+ 120hz 550Mhz 1100Mbps */
			qcom,mdss-dsi-panel-phy-timings = [00 24 0A 0A 1A 24 0A 0A 09 02 04 00 1E 0F];
			qcom,display-topology = <1 1 1>,<2 2 1>;
			qcom,default-topology-index = <1>;
		};
		timing@sa_fhd_90 { /* FHD+ 90hz 550Mhz 1100Mbps */
			qcom,mdss-dsi-panel-phy-timings = [00 24 0A 0A 1A 24 0A 0A 09 02 04 00 1E 0F];
			qcom,display-topology = <1 1 1>,<2 2 1>;
			qcom,default-topology-index = <1>;
		};
		timing@sa_fhd_60 { /* FHD+ 60hz 550Mhz 1100Mbps */
			qcom,mdss-dsi-panel-phy-timings = [00 24 0A 0A 1A 24 0A 0A 09 02 04 00 1E 0F];
			qcom,display-topology = <1 1 1>,<2 2 1>;
			qcom,default-topology-index = <1>;
		};
	};
};

&dsi_panel_AC306_S_3_A0020_dsc_cmd {
	/* adfr config */
	oplus,adfr-config = <0x4001>;  // 0b0100'0000'0000'0001
	oplus,adfr-test-te-gpio = <&tlmm 88 0>;
	/* just for qsync enable*/
	qcom,qsync-enable;
	qcom,mdss-dsi-qsync-min-refresh-rate = <30>;

	qcom,mdss-dsi-display-timings {
		timing@sa_fhd_120 { /* FHD+ 120hz 550Mhz 1100Mbps */
			/* standard adfr */
			qcom,mdss-dsi-h-sync-skew = <0>;
			oplus,adfr-min-fps-mapping-table = <120 60 30 20 10 1>;
			// oplus,adfr-idle-off-min-fps = <20>;
			oplus,adfr-high-precision-fps-mapping-table = <120 90 72 60>;

			qcom,mdss-dsi-adfr-min-fps-0-command = [
				39 00 00 40 00 00 04 FF 5A A5 2D
				39 00 00 40 00 00 03 83 00 00
				39 00 00 00 00 00 04 FF 5A A5 00
			];
			qcom,mdss-dsi-adfr-min-fps-1-command = [
				39 00 00 40 00 00 04 FF 5A A5 2D
				39 00 00 40 00 00 03 83 01 00
				39 00 00 00 00 00 04 FF 5A A5 00
			];
			qcom,mdss-dsi-adfr-min-fps-2-command = [
				39 00 00 40 00 00 04 FF 5A A5 2D
				39 00 00 40 00 00 03 83 03 00
				39 00 00 00 00 00 04 FF 5A A5 00
			];
			qcom,mdss-dsi-adfr-min-fps-3-command = [
				39 00 00 40 00 00 04 FF 5A A5 2D
				39 00 00 40 00 00 03 83 05 00
				39 00 00 00 00 00 04 FF 5A A5 00
			];
			qcom,mdss-dsi-adfr-min-fps-4-command = [
				39 00 00 40 00 00 04 FF 5A A5 2D
				39 00 00 40 00 00 03 83 0B 00
				39 00 00 00 00 00 04 FF 5A A5 00
			];
			qcom,mdss-dsi-adfr-min-fps-5-command = [
				39 00 00 40 00 00 04 FF 5A A5 2D
				39 00 00 40 00 00 03 83 77 00
				39 00 00 00 00 00 04 FF 5A A5 00
			];
			qcom,mdss-dsi-hpwm-adfr-min-fps-0-command = [
				39 00 00 40 00 00 04 FF 5A A5 2D
				39 00 00 40 00 00 03 83 00 00
				39 00 00 00 00 00 04 FF 5A A5 00
			];
			qcom,mdss-dsi-hpwm-adfr-min-fps-1-command = [
				39 00 00 40 00 00 04 FF 5A A5 2D
				39 00 00 40 00 00 03 83 01 00
				39 00 00 00 00 00 04 FF 5A A5 00
			];
			qcom,mdss-dsi-hpwm-adfr-min-fps-2-command = [
				39 00 00 40 00 00 04 FF 5A A5 2D
				39 00 00 40 00 00 03 83 03 00
				39 00 00 00 00 00 04 FF 5A A5 00
			];
			qcom,mdss-dsi-hpwm-adfr-min-fps-3-command = [
				39 00 00 40 00 00 04 FF 5A A5 2D
				39 00 00 40 00 00 03 83 05 00
				39 00 00 00 00 00 04 FF 5A A5 00
			];
			qcom,mdss-dsi-hpwm-adfr-min-fps-4-command = [
				39 00 00 40 00 00 04 FF 5A A5 2D
				39 00 00 40 00 00 03 83 0B 00
				39 00 00 00 00 00 04 FF 5A A5 00
			];
			qcom,mdss-dsi-hpwm-adfr-min-fps-5-command = [
				39 00 00 40 00 00 04 FF 5A A5 2D
				39 00 00 40 00 00 03 83 77 00
				39 00 00 00 00 00 04 FF 5A A5 00
			];

			qcom,mdss-dsi-adfr-min-fps-0-command-state = "dsi_hs_mode";
			qcom,mdss-dsi-adfr-min-fps-1-command-state = "dsi_hs_mode";
			qcom,mdss-dsi-adfr-min-fps-2-command-state = "dsi_hs_mode";
			qcom,mdss-dsi-adfr-min-fps-3-command-state = "dsi_hs_mode";
			qcom,mdss-dsi-adfr-min-fps-4-command-state = "dsi_hs_mode";
			qcom,mdss-dsi-adfr-min-fps-5-command-state = "dsi_hs_mode";
			qcom,mdss-dsi-hpwm-adfr-min-fps-0-command-state = "dsi_hs_mode";
			qcom,mdss-dsi-hpwm-adfr-min-fps-1-command-state = "dsi_hs_mode";
			qcom,mdss-dsi-hpwm-adfr-min-fps-2-command-state = "dsi_hs_mode";
			qcom,mdss-dsi-hpwm-adfr-min-fps-3-command-state = "dsi_hs_mode";
			qcom,mdss-dsi-hpwm-adfr-min-fps-4-command-state = "dsi_hs_mode";
			qcom,mdss-dsi-hpwm-adfr-min-fps-5-command-state = "dsi_hs_mode";
		};
		timing@sa_fhd_90 { /* FHD+ 90hz 550Mhz 1100Mbps */
			/* standard adfr */
			qcom,mdss-dsi-h-sync-skew = <0>;
			oplus,adfr-min-fps-mapping-table = <90 45 30 15 10 1>;
			// oplus,adfr-idle-off-min-fps = <30>;

			qcom,mdss-dsi-adfr-min-fps-0-command = [
				39 00 00 40 00 00 04 FF 5A A5 2D
				39 00 00 40 00 00 03 84 00 00
				39 00 00 00 00 00 04 FF 5A A5 00
			];
			qcom,mdss-dsi-adfr-min-fps-1-command = [
				39 00 00 40 00 00 04 FF 5A A5 2D
				39 00 00 40 00 00 03 84 01 00
				39 00 00 00 00 00 04 FF 5A A5 00
			];
			qcom,mdss-dsi-adfr-min-fps-2-command = [
				39 00 00 40 00 00 04 FF 5A A5 2D
				39 00 00 40 00 00 03 84 02 00
				39 00 00 00 00 00 04 FF 5A A5 00
			];
			qcom,mdss-dsi-adfr-min-fps-3-command = [
				39 00 00 40 00 00 04 FF 5A A5 2D
				39 00 00 40 00 00 03 84 05 00
				39 00 00 00 00 00 04 FF 5A A5 00
			];
			qcom,mdss-dsi-adfr-min-fps-4-command = [
				39 00 00 40 00 00 04 FF 5A A5 2D
				39 00 00 40 00 00 03 84 08 00
				39 00 00 00 00 00 04 FF 5A A5 00
			];
			qcom,mdss-dsi-adfr-min-fps-5-command = [
				39 00 00 40 00 00 04 FF 5A A5 2D
				39 00 00 40 00 00 03 84 59 00
				39 00 00 00 00 00 04 FF 5A A5 00
			];
			qcom,mdss-dsi-hpwm-adfr-min-fps-0-command = [
				39 00 00 40 00 00 04 FF 5A A5 2D
				39 00 00 40 00 00 03 84 00 00
				39 00 00 00 00 00 04 FF 5A A5 00
			];
			qcom,mdss-dsi-hpwm-adfr-min-fps-1-command = [
				39 00 00 40 00 00 04 FF 5A A5 2D
				39 00 00 40 00 00 03 84 01 00
				39 00 00 00 00 00 04 FF 5A A5 00
			];
			qcom,mdss-dsi-hpwm-adfr-min-fps-2-command = [
				39 00 00 40 00 00 04 FF 5A A5 2D
				39 00 00 40 00 00 03 84 02 00
				39 00 00 00 00 00 04 FF 5A A5 00
			];
			qcom,mdss-dsi-hpwm-adfr-min-fps-3-command = [
				39 00 00 40 00 00 04 FF 5A A5 2D
				39 00 00 40 00 00 03 84 05 00
				39 00 00 00 00 00 04 FF 5A A5 00
			];
			qcom,mdss-dsi-hpwm-adfr-min-fps-4-command = [
				39 00 00 40 00 00 04 FF 5A A5 2D
				39 00 00 40 00 00 03 84 08 00
				39 00 00 00 00 00 04 FF 5A A5 00
			];
			qcom,mdss-dsi-hpwm-adfr-min-fps-5-command = [
				39 00 00 40 00 00 04 FF 5A A5 2D
				39 00 00 40 00 00 03 84 59 00
				39 00 00 00 00 00 04 FF 5A A5 00
			];

			qcom,mdss-dsi-adfr-min-fps-0-command-state = "dsi_hs_mode";
			qcom,mdss-dsi-adfr-min-fps-1-command-state = "dsi_hs_mode";
			qcom,mdss-dsi-adfr-min-fps-2-command-state = "dsi_hs_mode";
			qcom,mdss-dsi-adfr-min-fps-3-command-state = "dsi_hs_mode";
			qcom,mdss-dsi-adfr-min-fps-4-command-state = "dsi_hs_mode";
			qcom,mdss-dsi-adfr-min-fps-5-command-state = "dsi_hs_mode";
			qcom,mdss-dsi-hpwm-adfr-min-fps-0-command-state = "dsi_hs_mode";
			qcom,mdss-dsi-hpwm-adfr-min-fps-1-command-state = "dsi_hs_mode";
			qcom,mdss-dsi-hpwm-adfr-min-fps-2-command-state = "dsi_hs_mode";
			qcom,mdss-dsi-hpwm-adfr-min-fps-3-command-state = "dsi_hs_mode";
			qcom,mdss-dsi-hpwm-adfr-min-fps-4-command-state = "dsi_hs_mode";
			qcom,mdss-dsi-hpwm-adfr-min-fps-5-command-state = "dsi_hs_mode";
		};
		timing@sa_fhd_60 { /* FHD+ 60hz 550Mhz 1100Mbps */
			/* standard adfr */
			qcom,mdss-dsi-h-sync-skew = <1>;
			oplus,adfr-min-fps-mapping-table = <60 40 30 20 10 1>;
			// oplus,adfr-idle-off-min-fps = <20>;

			qcom,mdss-dsi-adfr-min-fps-0-command = [
				39 00 00 40 00 00 04 FF 5A A5 2D
				39 00 00 40 00 00 03 83 01 00
				39 00 00 00 00 00 04 FF 5A A5 00
			];
			qcom,mdss-dsi-adfr-min-fps-1-command = [
				39 00 00 40 00 00 04 FF 5A A5 2D
				39 00 00 40 00 00 03 83 02 00
				39 00 00 00 00 00 04 FF 5A A5 00
			];
			qcom,mdss-dsi-adfr-min-fps-2-command = [
				39 00 00 40 00 00 04 FF 5A A5 2D
				39 00 00 40 00 00 03 83 03 00
				39 00 00 00 00 00 04 FF 5A A5 00
			];
			qcom,mdss-dsi-adfr-min-fps-3-command = [
				39 00 00 40 00 00 04 FF 5A A5 2D
				39 00 00 40 00 00 03 83 05 00
				39 00 00 00 00 00 04 FF 5A A5 00
			];
			qcom,mdss-dsi-adfr-min-fps-4-command = [
				39 00 00 40 00 00 04 FF 5A A5 2D
				39 00 00 40 00 00 03 83 0B 00
				39 00 00 00 00 00 04 FF 5A A5 00
			];
			qcom,mdss-dsi-adfr-min-fps-5-command = [
				39 00 00 40 00 00 04 FF 5A A5 2D
				39 00 00 40 00 00 03 83 77 00
				39 00 00 00 00 00 04 FF 5A A5 00
			];
			qcom,mdss-dsi-hpwm-adfr-min-fps-0-command = [
				39 00 00 40 00 00 04 FF 5A A5 2D
				39 00 00 40 00 00 03 83 01 00
				39 00 00 00 00 00 04 FF 5A A5 00
			];
			qcom,mdss-dsi-hpwm-adfr-min-fps-1-command = [
				39 00 00 40 00 00 04 FF 5A A5 2D
				39 00 00 40 00 00 03 83 02 00
				39 00 00 00 00 00 04 FF 5A A5 00
			];
			qcom,mdss-dsi-hpwm-adfr-min-fps-2-command = [
				39 00 00 40 00 00 04 FF 5A A5 2D
				39 00 00 40 00 00 03 83 03 00
				39 00 00 00 00 00 04 FF 5A A5 00
			];
			qcom,mdss-dsi-hpwm-adfr-min-fps-3-command = [
				39 00 00 40 00 00 04 FF 5A A5 2D
				39 00 00 40 00 00 03 83 05 00
				39 00 00 00 00 00 04 FF 5A A5 00
			];
			qcom,mdss-dsi-hpwm-adfr-min-fps-4-command = [
				39 00 00 40 00 00 04 FF 5A A5 2D
				39 00 00 40 00 00 03 83 0B 00
				39 00 00 00 00 00 04 FF 5A A5 00
			];
			qcom,mdss-dsi-hpwm-adfr-min-fps-5-command = [
				39 00 00 40 00 00 04 FF 5A A5 2D
				39 00 00 40 00 00 03 83 77 00
				39 00 00 00 00 00 04 FF 5A A5 00
			];

			qcom,mdss-dsi-adfr-min-fps-0-command-state = "dsi_hs_mode";
			qcom,mdss-dsi-adfr-min-fps-1-command-state = "dsi_hs_mode";
			qcom,mdss-dsi-adfr-min-fps-2-command-state = "dsi_hs_mode";
			qcom,mdss-dsi-adfr-min-fps-3-command-state = "dsi_hs_mode";
			qcom,mdss-dsi-adfr-min-fps-4-command-state = "dsi_hs_mode";
			qcom,mdss-dsi-adfr-min-fps-5-command-state = "dsi_hs_mode";
			qcom,mdss-dsi-hpwm-adfr-min-fps-0-command-state = "dsi_hs_mode";
			qcom,mdss-dsi-hpwm-adfr-min-fps-1-command-state = "dsi_hs_mode";
			qcom,mdss-dsi-hpwm-adfr-min-fps-2-command-state = "dsi_hs_mode";
			qcom,mdss-dsi-hpwm-adfr-min-fps-3-command-state = "dsi_hs_mode";
			qcom,mdss-dsi-hpwm-adfr-min-fps-4-command-state = "dsi_hs_mode";
			qcom,mdss-dsi-hpwm-adfr-min-fps-5-command-state = "dsi_hs_mode";
		};
	};
};

&dsi_panel_AC306_S_3_A0020_dsc_cmd {
	qcom,panel_voltage_vddi_name = "vddio";
	qcom,panel_voltage_vddi = <0 1700000 1800000 1900000>;
//	qcom,panel_voltage_vddr_name = "vci";
//	qcom,panel_voltage_vddr = <1 3000000 3200000 3300000>;
};

&dsi_panel_AC306_S_3_A0020_dsc_cmd {
	oplus,color_vivid_status;
	oplus,color_srgb_status;
	oplus,color_oplus_calibrate_status;
	oplus,color_dual_panel_status;
	oplus,color_dual_brightness_status;
	oplus,color_loading_status;
	oplus,color_2nit_status;
	oplus,mdss-dsi-panel-type = <0>;

	/* OPLUS FEATURES CONFIG */
	oplus,dp-enabled;
	oplus,enhance_mipi_strength;

	oplus,panel-60hz-timing-switch-frame-delay;

	/* pwm config */
	oplus,pwm-switch-config = <0x01000001>;
	oplus,pwm-switch-mode0-states-info = <2 1146 1>;

	/* ESD CONFIG */
	qcom,esd-check-enabled;
	qcom,mdss-dsi-panel-status-check-mode = "reg_read";
	qcom,mdss-dsi-panel-status-command = [
		06 00 00 00 00 00 01 0A
	];
	qcom,mdss-dsi-panel-status-command-state = "dsi_lp_mode";
	qcom,mdss-dsi-panel-status-value = <
		0x9C
	>;
	qcom,mdss-dsi-panel-status-read-length = <1>;
	oplus,mdss-dsi-panel-status-match-modes = <0x00000000>;

	/* MIPI ERR check config */
	/*  BIT(0): enable/disable check
	 ** BIT(1): enable/disable page switch
	 */
	oplus,mipi-err-check-config = <0x03>; // 0b0000'0011
	oplus,mipi-err-check-reg = [
		0E
	];
	oplus,mipi-err-check-value = [
		80
	];
	oplus,mipi-err-check-count = [
		01
	];
	/* 32-bit binary flag
	 ** Bit value identified how to match the return value of each register.
	 ** The value 0(default) means equal, and the value 1 means not equal.
	 */
	oplus,mipi-err-check-match-modes = <0x00000000>;

	/* serial num config */
	oplus,dsi-serial-number-enabled;
	oplus,dsi-serial-number-switch-page;
	oplus,dsi-serial-number-index= <0>;
	oplus,dsi-serial-number-reg= <0x80>;
	oplus,dsi-serial-number-read-count= <7>;
	oplus,dsi-serial-number-base-year = <2020>;

	/* btb-sn config */
	oplus,dsi-btb-sn-enabled;
	oplus,dsi-btb-sn-switch-page;
	oplus,dsi-btb-sn-reg= <0x82>;
	oplus,dsi-btb-sn-index= <0>;
	oplus,dsi-btb-sn-read-count= <32>;

	/* SPR CONFIG */
	qcom,spr-pack-type = "pentile";
};
